VERSION ""

NS_ :

BS_:

BU_: Vector__XXX

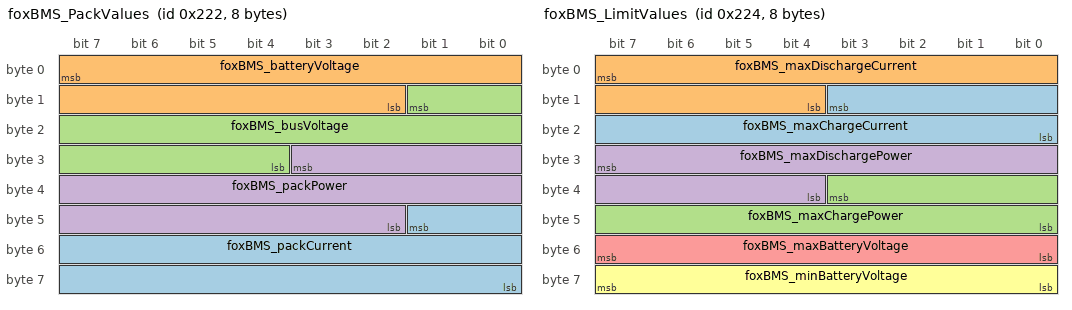
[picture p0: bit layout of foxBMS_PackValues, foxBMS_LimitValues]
BO_ 546 foxBMS_PackValues: 8 Vector__XXX
SG_ foxBMS_packCurrent : 41|18@0- (0.01,0) [-1310.72|1310.71] "A" Vector__XXX
SG_ foxBMS_batteryVoltage : 7|14@0+ (0.1,0) [0|1638.3] "V" Vector__XXX
SG_ foxBMS_busVoltage : 9|14@0+ (0.1,0) [0|1638.3] "V" Vector__XXX
SG_ foxBMS_packPower : 27|18@0- (0.01,0) [-1310.72|1310.71] "kW" Vector__XXX

BO_ 548 foxBMS_LimitValues: 8 Vector__XXX
SG_ foxBMS_maxChargeCurrent : 11|12@0+ (0.25,0) [0|1023.75] "A" Vector__XXX
SG_ foxBMS_maxDischargeCurrent : 7|12@0+ (0.25,0) [0|1023.75] "A" Vector__XXX
SG_ foxBMS_maxChargePower : 35|12@0+ (0.2,0) [0|819] "kW" Vector__XXX
SG_ foxBMS_maxDischargePower : 31|12@0+ (0.1,0) [0|409.5] "kW" Vector__XXX
SG_ foxBMS_maxBatteryVoltage : 55|8@0+ (4,0) [0|1020] "V" Vector__XXX
SG_ foxBMS_minBatteryVoltage : 63|8@0+ (4,0) [0|1020] "V" Vector__XXX

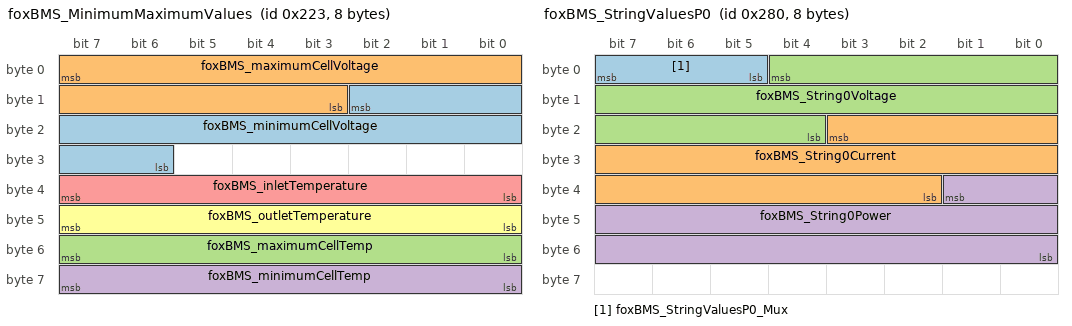
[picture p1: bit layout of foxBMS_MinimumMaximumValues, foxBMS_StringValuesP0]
BO_ 547 foxBMS_MinimumMaximumValues: 8 Vector__XXX
SG_ foxBMS_minimumCellVoltage : 10|13@0+ (1,0) [0|8191] "mV" Vector__XXX
SG_ foxBMS_maximumCellVoltage : 7|13@0+ (1,0) [0|8191] "mV" Vector__XXX
SG_ foxBMS_maximumCellTemp : 55|8@0- (1,0) [-128|127] "degC" Vector__XXX
SG_ foxBMS_minimumCellTemp : 63|8@0- (1,0) [-128|127] "degC" Vector__XXX
SG_ foxBMS_inletTemperature : 39|8@0- (1,0) [-128|127] "degC" Vector__XXX
SG_ foxBMS_outletTemperature : 47|8@0- (1,0) [-128|127] "degC" Vector__XXX

BO_ 640 foxBMS_StringValuesP0: 8 Vector__XXX
SG_ foxBMS_StringValuesP0_Mux M : 7|3@0+ (1,0) [0|0] "" Vector__XXX
SG_ foxBMS_String0Current : 19|18@0- (0.01,0) [-1310.72|1310.71] "A" Vector__XXX
SG_ foxBMS_String0Voltage : 4|17@0+ (0.01,0) [0|1310.71] "V" Vector__XXX
SG_ foxBMS_String0Power : 33|18@0- (0.01,0) [-1310.72|1310.71] "kW" Vector__XXX

BO_ 643 foxBMS_StringValuesP1: 8 Vector__XXX
SG_ foxBMS_StringValuesP1_Mux M : 7|4@0+ (1,0) [0|0] "" Vector__XXX
SG_ foxBMS_String0EnergyCount : 15|32@0- (1,0) [-2147483648|2147483647] "Wh" Vector__XXX

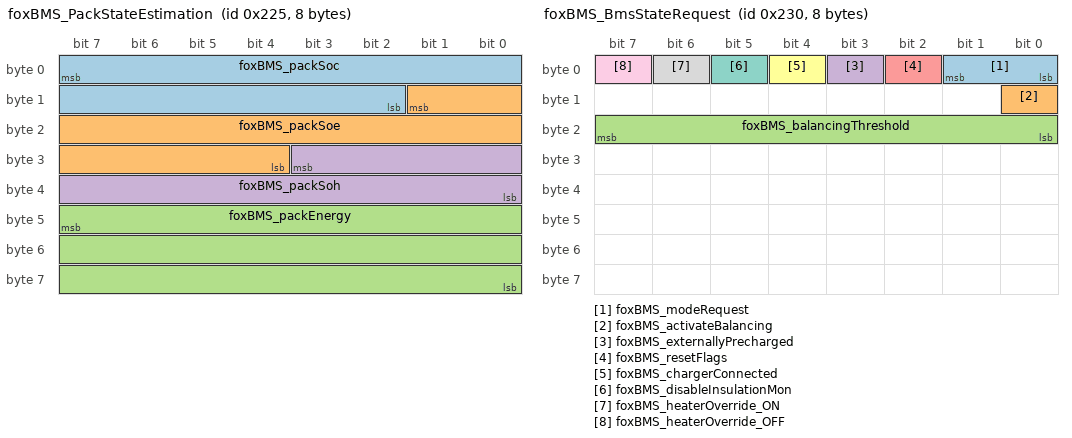
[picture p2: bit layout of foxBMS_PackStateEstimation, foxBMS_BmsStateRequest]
BO_ 549 foxBMS_PackStateEstimation: 8 Vector__XXX
SG_ foxBMS_packSoc : 7|14@0+ (0.01,0) [0|163.83] "%" Vector__XXX
SG_ foxBMS_packSoe : 9|14@0+ (0.01,0) [0|163.83] "%" Vector__XXX
SG_ foxBMS_packEnergy : 47|24@0+ (0.01,0) [0|167772.15] "kWh" Vector__XXX
SG_ foxBMS_packSoh : 27|12@0+ (0.025,0) [0|102.375] "%" Vector__XXX

BO_ 576 foxBMS_CellVoltages: 8 Vector__XXX
SG_ foxBMS_CellVoltages_Mux M : 7|8@0+ (1,0) [0|0] "" Vector__XXX
SG_ cellVoltage_000_invalidFlag m0 : 12|1@0+ (1,0) [0|1] "" Vector__XXX
SG_ cellVoltage_001_invalidFlag m0 : 13|1@0+ (1,0) [0|1] "" Vector__XXX
SG_ cellVoltage_002_invalidFlag m0 : 14|1@0+ (1,0) [0|1] "" Vector__XXX
SG_ cellVoltage_003_invalidFlag m0 : 15|1@0+ (1,0) [0|1] "" Vector__XXX
SG_ cellVoltage_000 m0 : 11|13@0+ (1,0) [0|8191] "mV" Vector__XXX
SG_ cellVoltage_001 m0 : 30|13@0+ (1,0) [0|8191] "mV" Vector__XXX
SG_ cellVoltage_002 m0 : 33|13@0+ (1,0) [0|8191] "mV" Vector__XXX
SG_ cellVoltage_003 m0 : 52|13@0+ (1,0) [0|8191] "mV" Vector__XXX
SG_ cellVoltage_004_invalidFlag m1 : 12|1@0+ (1,0) [0|1] "" Vector__XXX
SG_ cellVoltage_005_invalidFlag m1 : 13|1@0+ (1,0) [0|1] "" Vector__XXX
SG_ cellVoltage_006_invalidFlag m1 : 14|1@0+ (1,0) [0|1] "" Vector__XXX
SG_ cellVoltage_007_invalidFlag m1 : 15|1@0+ (1,0) [0|1] "" Vector__XXX
SG_ cellVoltage_004 m1 : 11|13@0+ (1,0) [0|8191] "mV" Vector__XXX
SG_ cellVoltage_005 m1 : 30|13@0+ (1,0) [0|8191] "mV" Vector__XXX
SG_ cellVoltage_006 m1 : 33|13@0+ (1,0) [0|8191] "mV" Vector__XXX
SG_ cellVoltage_007 m1 : 52|13@0+ (1,0) [0|8191] "mV" Vector__XXX
SG_ cellVoltage_008_invalidFlag m2 : 12|1@0+ (1,0) [0|1] "" Vector__XXX
SG_ cellVoltage_009_invalidFlag m2 : 13|1@0+ (1,0) [0|1] "" Vector__XXX
SG_ cellVoltage_010_invalidFlag m2 : 14|1@0+ (1,0) [0|1] "" Vector__XXX
SG_ cellVoltage_011_invalidFlag m2 : 15|1@0+ (1,0) [0|1] "" Vector__XXX
SG_ cellVoltage_008 m2 : 11|13@0+ (1,0) [0|8191] "mV" Vector__XXX
SG_ cellVoltage_009 m2 : 30|13@0+ (1,0) [0|8191] "mV" Vector__XXX
SG_ cellVoltage_010 m2 : 33|13@0+ (1,0) [0|8191] "mV" Vector__XXX
SG_ cellVoltage_011 m2 : 52|13@0+ (1,0) [0|8191] "mV" Vector__XXX
SG_ cellVoltage_012_invalidFlag m3 : 12|1@0+ (1,0) [0|1] "" Vector__XXX
SG_ cellVoltage_013_invalidFlag m3 : 13|1@0+ (1,0) [0|1] "" Vector__XXX
SG_ cellVoltage_014_invalidFlag m3 : 14|1@0+ (1,0) [0|1] "" Vector__XXX
SG_ cellVoltage_015_invalidFlag m3 : 15|1@0+ (1,0) [0|1] "" Vector__XXX
SG_ cellVoltage_012 m3 : 11|13@0+ (1,0) [0|8191] "mV" Vector__XXX
SG_ cellVoltage_013 m3 : 30|13@0+ (1,0) [0|8191] "mV" Vector__XXX
SG_ cellVoltage_014 m3 : 33|13@0+ (1,0) [0|8191] "mV" Vector__XXX
SG_ cellVoltage_015 m3 : 52|13@0+ (1,0) [0|8191] "mV" Vector__XXX
SG_ cellVoltage_016_invalidFlag m4 : 12|1@0+ (1,0) [0|1] "" Vector__XXX
SG_ cellVoltage_017_invalidFlag m4 : 13|1@0+ (1,0) [0|1] "" Vector__XXX
SG_ cellVoltage_018_invalidFlag m4 : 14|1@0+ (1,0) [0|1] "" Vector__XXX
SG_ cellVoltage_019_invalidFlag m4 : 15|1@0+ (1,0) [0|1] "" Vector__XXX
SG_ cellVoltage_016 m4 : 11|13@0+ (1,0) [0|8191] "mV" Vector__XXX
SG_ cellVoltage_017 m4 : 30|13@0+ (1,0) [0|8191] "mV" Vector__XXX
SG_ cellVoltage_018 m4 : 33|13@0+ (1,0) [0|8191] "mV" Vector__XXX
SG_ cellVoltage_019 m4 : 52|13@0+ (1,0) [0|8191] "mV" Vector__XXX
SG_ cellVoltage_020_invalidFlag m5 : 12|1@0+ (1,0) [0|1] "" Vector__XXX
SG_ cellVoltage_021_invalidFlag m5 : 13|1@0+ (1,0) [0|1] "" Vector__XXX
SG_ cellVoltage_022_invalidFlag m5 : 14|1@0+ (1,0) [0|1] "" Vector__XXX
SG_ cellVoltage_023_invalidFlag m5 : 15|1@0+ (1,0) [0|1] "" Vector__XXX
SG_ cellVoltage_020 m5 : 11|13@0+ (1,0) [0|8191] "mV" Vector__XXX
SG_ cellVoltage_021 m5 : 30|13@0+ (1,0) [0|8191] "mV" Vector__XXX
SG_ cellVoltage_022 m5 : 33|13@0+ (1,0) [0|8191] "mV" Vector__XXX
SG_ cellVoltage_023 m5 : 52|13@0+ (1,0) [0|8191] "mV" Vector__XXX
SG_ cellVoltage_024_invalidFlag m6 : 12|1@0+ (1,0) [0|1] "" Vector__XXX
SG_ cellVoltage_025_invalidFlag m6 : 13|1@0+ (1,0) [0|1] "" Vector__XXX
SG_ cellVoltage_026_invalidFlag m6 : 14|1@0+ (1,0) [0|1] "" Vector__XXX
SG_ cellVoltage_027_invalidFlag m6 : 15|1@0+ (1,0) [0|1] "" Vector__XXX
SG_ cellVoltage_024 m6 : 11|13@0+ (1,0) [0|8191] "mV" Vector__XXX
SG_ cellVoltage_025 m6 : 30|13@0+ (1,0) [0|8191] "mV" Vector__XXX
SG_ cellVoltage_026 m6 : 33|13@0+ (1,0) [0|8191] "mV" Vector__XXX
SG_ cellVoltage_027 m6 : 52|13@0+ (1,0) [0|8191] "mV" Vector__XXX
SG_ cellVoltage_028_invalidFlag m7 : 12|1@0+ (1,0) [0|1] "" Vector__XXX
SG_ cellVoltage_029_invalidFlag m7 : 13|1@0+ (1,0) [0|1] "" Vector__XXX
SG_ cellVoltage_030_invalidFlag m7 : 14|1@0+ (1,0) [0|1] "" Vector__XXX
SG_ cellVoltage_031_invalidFlag m7 : 15|1@0+ (1,0) [0|1] "" Vector__XXX
SG_ cellVoltage_028 m7 : 11|13@0+ (1,0) [0|8191] "mV" Vector__XXX
SG_ cellVoltage_029 m7 : 30|13@0+ (1,0) [0|8191] "mV" Vector__XXX
SG_ cellVoltage_030 m7 : 33|13@0+ (1,0) [0|8191] "mV" Vector__XXX
SG_ cellVoltage_031 m7 : 52|13@0+ (1,0) [0|8191] "mV" Vector__XXX
SG_ cellVoltage_032_invalidFlag m8 : 12|1@0+ (1,0) [0|1] "" Vector__XXX
SG_ cellVoltage_033_invalidFlag m8 : 13|1@0+ (1,0) [0|1] "" Vector__XXX
SG_ cellVoltage_034_invalidFlag m8 : 14|1@0+ (1,0) [0|1] "" Vector__XXX
SG_ cellVoltage_035_invalidFlag m8 : 15|1@0+ (1,0) [0|1] "" Vector__XXX
SG_ cellVoltage_032 m8 : 11|13@0+ (1,0) [0|8191] "mV" Vector__XXX
SG_ cellVoltage_033 m8 : 30|13@0+ (1,0) [0|8191] "mV" Vector__XXX
SG_ cellVoltage_034 m8 : 33|13@0+ (1,0) [0|8191] "mV" Vector__XXX
SG_ cellVoltage_035 m8 : 52|13@0+ (1,0) [0|8191] "mV" Vector__XXX
SG_ cellVoltage_036_invalidFlag m9 : 12|1@0+ (1,0) [0|1] "" Vector__XXX
SG_ cellVoltage_037_invalidFlag m9 : 13|1@0+ (1,0) [0|1] "" Vector__XXX
SG_ cellVoltage_038_invalidFlag m9 : 14|1@0+ (1,0) [0|1] "" Vector__XXX
SG_ cellVoltage_039_invalidFlag m9 : 15|1@0+ (1,0) [0|1] "" Vector__XXX
SG_ cellVoltage_036 m9 : 11|13@0+ (1,0) [0|8191] "mV" Vector__XXX
SG_ cellVoltage_037 m9 : 30|13@0+ (1,0) [0|8191] "mV" Vector__XXX
SG_ cellVoltage_038 m9 : 33|13@0+ (1,0) [0|8191] "mV" Vector__XXX
SG_ cellVoltage_039 m9 : 52|13@0+ (1,0) [0|8191] "mV" Vector__XXX
SG_ cellVoltage_040_invalidFlag m10 : 12|1@0+ (1,0) [0|1] "" Vector__XXX
SG_ cellVoltage_041_invalidFlag m10 : 13|1@0+ (1,0) [0|1] "" Vector__XXX
SG_ cellVoltage_042_invalidFlag m10 : 14|1@0+ (1,0) [0|1] "" Vector__XXX
SG_ cellVoltage_043_invalidFlag m10 : 15|1@0+ (1,0) [0|1] "" Vector__XXX
SG_ cellVoltage_040 m10 : 11|13@0+ (1,0) [0|8191] "mV" Vector__XXX
SG_ cellVoltage_041 m10 : 30|13@0+ (1,0) [0|8191] "mV" Vector__XXX
SG_ cellVoltage_042 m10 : 33|13@0+ (1,0) [0|8191] "mV" Vector__XXX
SG_ cellVoltage_043 m10 : 52|13@0+ (1,0) [0|8191] "mV" Vector__XXX
SG_ cellVoltage_044_invalidFlag m11 : 12|1@0+ (1,0) [0|1] "" Vector__XXX
SG_ cellVoltage_045_invalidFlag m11 : 13|1@0+ (1,0) [0|1] "" Vector__XXX
SG_ cellVoltage_046_invalidFlag m11 : 14|1@0+ (1,0) [0|1] "" Vector__XXX
SG_ cellVoltage_047_invalidFlag m11 : 15|1@0+ (1,0) [0|1] "" Vector__XXX
SG_ cellVoltage_044 m11 : 11|13@0+ (1,0) [0|8191] "mV" Vector__XXX
SG_ cellVoltage_045 m11 : 30|13@0+ (1,0) [0|8191] "mV" Vector__XXX
SG_ cellVoltage_046 m11 : 33|13@0+ (1,0) [0|8191] "mV" Vector__XXX
SG_ cellVoltage_047 m11 : 52|13@0+ (1,0) [0|8191] "mV" Vector__XXX
SG_ cellVoltage_048_invalidFlag m12 : 12|1@0+ (1,0) [0|1] "" Vector__XXX
SG_ cellVoltage_049_invalidFlag m12 : 13|1@0+ (1,0) [0|1] "" Vector__XXX
SG_ cellVoltage_050_invalidFlag m12 : 14|1@0+ (1,0) [0|1] "" Vector__XXX
SG_ cellVoltage_051_invalidFlag m12 : 15|1@0+ (1,0) [0|1] "" Vector__XXX
SG_ cellVoltage_048 m12 : 11|13@0+ (1,0) [0|8191] "mV" Vector__XXX
SG_ cellVoltage_049 m12 : 30|13@0+ (1,0) [0|8191] "mV" Vector__XXX
SG_ cellVoltage_050 m12 : 33|13@0+ (1,0) [0|8191] "mV" Vector__XXX
SG_ cellVoltage_051 m12 : 52|13@0+ (1,0) [0|8191] "mV" Vector__XXX
SG_ cellVoltage_052_invalidFlag m13 : 12|1@0+ (1,0) [0|1] "" Vector__XXX
SG_ cellVoltage_053_invalidFlag m13 : 13|1@0+ (1,0) [0|1] "" Vector__XXX
SG_ cellVoltage_054_invalidFlag m13 : 14|1@0+ (1,0) [0|1] "" Vector__XXX
SG_ cellVoltage_055_invalidFlag m13 : 15|1@0+ (1,0) [0|1] "" Vector__XXX
SG_ cellVoltage_052 m13 : 11|13@0+ (1,0) [0|8191] "mV" Vector__XXX
SG_ cellVoltage_053 m13 : 30|13@0+ (1,0) [0|8191] "mV" Vector__XXX
SG_ cellVoltage_054 m13 : 33|13@0+ (1,0) [0|8191] "mV" Vector__XXX
SG_ cellVoltage_055 m13 : 52|13@0+ (1,0) [0|8191] "mV" Vector__XXX
SG_ cellVoltage_056_invalidFlag m14 : 12|1@0+ (1,0) [0|1] "" Vector__XXX
SG_ cellVoltage_057_invalidFlag m14 : 13|1@0+ (1,0) [0|1] "" Vector__XXX
SG_ cellVoltage_058_invalidFlag m14 : 14|1@0+ (1,0) [0|1] "" Vector__XXX
SG_ cellVoltage_059_invalidFlag m14 : 15|1@0+ (1,0) [0|1] "" Vector__XXX
SG_ cellVoltage_056 m14 : 11|13@0+ (1,0) [0|8191] "mV" Vector__XXX
SG_ cellVoltage_057 m14 : 30|13@0+ (1,0) [0|8191] "mV" Vector__XXX
SG_ cellVoltage_058 m14 : 33|13@0+ (1,0) [0|8191] "mV" Vector__XXX
SG_ cellVoltage_059 m14 : 52|13@0+ (1,0) [0|8191] "mV" Vector__XXX
SG_ cellVoltage_060_invalidFlag m15 : 12|1@0+ (1,0) [0|1] "" Vector__XXX
SG_ cellVoltage_061_invalidFlag m15 : 13|1@0+ (1,0) [0|1] "" Vector__XXX
SG_ cellVoltage_062_invalidFlag m15 : 14|1@0+ (1,0) [0|1] "" Vector__XXX
SG_ cellVoltage_063_invalidFlag m15 : 15|1@0+ (1,0) [0|1] "" Vector__XXX
SG_ cellVoltage_060 m15 : 11|13@0+ (1,0) [0|8191] "mV" Vector__XXX
SG_ cellVoltage_061 m15 : 30|13@0+ (1,0) [0|8191] "mV" Vector__XXX
SG_ cellVoltage_062 m15 : 33|13@0+ (1,0) [0|8191] "mV" Vector__XXX
SG_ cellVoltage_063 m15 : 52|13@0+ (1,0) [0|8191] "mV" Vector__XXX
SG_ cellVoltage_064_invalidFlag m16 : 12|1@0+ (1,0) [0|1] "" Vector__XXX
SG_ cellVoltage_065_invalidFlag m16 : 13|1@0+ (1,0) [0|1] "" Vector__XXX
SG_ cellVoltage_066_invalidFlag m16 : 14|1@0+ (1,0) [0|1] "" Vector__XXX
SG_ cellVoltage_067_invalidFlag m16 : 15|1@0+ (1,0) [0|1] "" Vector__XXX
SG_ cellVoltage_064 m16 : 11|13@0+ (1,0) [0|8191] "mV" Vector__XXX
SG_ cellVoltage_065 m16 : 30|13@0+ (1,0) [0|8191] "mV" Vector__XXX
SG_ cellVoltage_066 m16 : 33|13@0+ (1,0) [0|8191] "mV" Vector__XXX
SG_ cellVoltage_067 m16 : 52|13@0+ (1,0) [0|8191] "mV" Vector__XXX
SG_ cellVoltage_068_invalidFlag m17 : 12|1@0+ (1,0) [0|1] "" Vector__XXX
SG_ cellVoltage_069_invalidFlag m17 : 13|1@0+ (1,0) [0|1] "" Vector__XXX
SG_ cellVoltage_070_invalidFlag m17 : 14|1@0+ (1,0) [0|1] "" Vector__XXX
SG_ cellVoltage_071_invalidFlag m17 : 15|1@0+ (1,0) [0|1] "" Vector__XXX
SG_ cellVoltage_068 m17 : 11|13@0+ (1,0) [0|8191] "mV" Vector__XXX
SG_ cellVoltage_069 m17 : 30|13@0+ (1,0) [0|8191] "mV" Vector__XXX
SG_ cellVoltage_070 m17 : 33|13@0+ (1,0) [0|8191] "mV" Vector__XXX
SG_ cellVoltage_071 m17 : 52|13@0+ (1,0) [0|8191] "mV" Vector__XXX
SG_ cellVoltage_072_invalidFlag m18 : 12|1@0+ (1,0) [0|1] "" Vector__XXX
SG_ cellVoltage_073_invalidFlag m18 : 13|1@0+ (1,0) [0|1] "" Vector__XXX
SG_ cellVoltage_074_invalidFlag m18 : 14|1@0+ (1,0) [0|1] "" Vector__XXX
SG_ cellVoltage_075_invalidFlag m18 : 15|1@0+ (1,0) [0|1] "" Vector__XXX
SG_ cellVoltage_072 m18 : 11|13@0+ (1,0) [0|8191] "mV" Vector__XXX
SG_ cellVoltage_073 m18 : 30|13@0+ (1,0) [0|8191] "mV" Vector__XXX
SG_ cellVoltage_074 m18 : 33|13@0+ (1,0) [0|8191] "mV" Vector__XXX
SG_ cellVoltage_075 m18 : 52|13@0+ (1,0) [0|8191] "mV" Vector__XXX
SG_ cellVoltage_076_invalidFlag m19 : 12|1@0+ (1,0) [0|1] "" Vector__XXX
SG_ cellVoltage_077_invalidFlag m19 : 13|1@0+ (1,0) [0|1] "" Vector__XXX
SG_ cellVoltage_078_invalidFlag m19 : 14|1@0+ (1,0) [0|1] "" Vector__XXX
SG_ cellVoltage_079_invalidFlag m19 : 15|1@0+ (1,0) [0|1] "" Vector__XXX
SG_ cellVoltage_076 m19 : 11|13@0+ (1,0) [0|8191] "mV" Vector__XXX
SG_ cellVoltage_077 m19 : 30|13@0+ (1,0) [0|8191] "mV" Vector__XXX
SG_ cellVoltage_078 m19 : 33|13@0+ (1,0) [0|8191] "mV" Vector__XXX
SG_ cellVoltage_079 m19 : 52|13@0+ (1,0) [0|8191] "mV" Vector__XXX
SG_ cellVoltage_080_invalidFlag m20 : 12|1@0+ (1,0) [0|1] "" Vector__XXX
SG_ cellVoltage_081_invalidFlag m20 : 13|1@0+ (1,0) [0|1] "" Vector__XXX
SG_ cellVoltage_082_invalidFlag m20 : 14|1@0+ (1,0) [0|1] "" Vector__XXX
SG_ cellVoltage_083_invalidFlag m20 : 15|1@0+ (1,0) [0|1] "" Vector__XXX
SG_ cellVoltage_080 m20 : 11|13@0+ (1,0) [0|8191] "mV" Vector__XXX
SG_ cellVoltage_081 m20 : 30|13@0+ (1,0) [0|8191] "mV" Vector__XXX
SG_ cellVoltage_082 m20 : 33|13@0+ (1,0) [0|8191] "mV" Vector__XXX
SG_ cellVoltage_083 m20 : 52|13@0+ (1,0) [0|8191] "mV" Vector__XXX
SG_ cellVoltage_084_invalidFlag m21 : 12|1@0+ (1,0) [0|1] "" Vector__XXX
SG_ cellVoltage_085_invalidFlag m21 : 13|1@0+ (1,0) [0|1] "" Vector__XXX
SG_ cellVoltage_086_invalidFlag m21 : 14|1@0+ (1,0) [0|1] "" Vector__XXX
SG_ cellVoltage_087_invalidFlag m21 : 15|1@0+ (1,0) [0|1] "" Vector__XXX
SG_ cellVoltage_084 m21 : 11|13@0+ (1,0) [0|8191] "mV" Vector__XXX
SG_ cellVoltage_085 m21 : 30|13@0+ (1,0) [0|8191] "mV" Vector__XXX
SG_ cellVoltage_086 m21 : 33|13@0+ (1,0) [0|8191] "mV" Vector__XXX
SG_ cellVoltage_087 m21 : 52|13@0+ (1,0) [0|8191] "mV" Vector__XXX
SG_ cellVoltage_088_invalidFlag m22 : 12|1@0+ (1,0) [0|1] "" Vector__XXX
SG_ cellVoltage_089_invalidFlag m22 : 13|1@0+ (1,0) [0|1] "" Vector__XXX
SG_ cellVoltage_090_invalidFlag m22 : 14|1@0+ (1,0) [0|1] "" Vector__XXX
SG_ cellVoltage_091_invalidFlag m22 : 15|1@0+ (1,0) [0|1] "" Vector__XXX
SG_ cellVoltage_088 m22 : 11|13@0+ (1,0) [0|8191] "mV" Vector__XXX
SG_ cellVoltage_089 m22 : 30|13@0+ (1,0) [0|8191] "mV" Vector__XXX
SG_ cellVoltage_090 m22 : 33|13@0+ (1,0) [0|8191] "mV" Vector__XXX
SG_ cellVoltage_091 m22 : 52|13@0+ (1,0) [0|8191] "mV" Vector__XXX
SG_ cellVoltage_092_invalidFlag m23 : 12|1@0+ (1,0) [0|1] "" Vector__XXX
SG_ cellVoltage_093_invalidFlag m23 : 13|1@0+ (1,0) [0|1] "" Vector__XXX
SG_ cellVoltage_094_invalidFlag m23 : 14|1@0+ (1,0) [0|1] "" Vector__XXX
SG_ cellVoltage_095_invalidFlag m23 : 15|1@0+ (1,0) [0|1] "" Vector__XXX
SG_ cellVoltage_092 m23 : 11|13@0+ (1,0) [0|8191] "mV" Vector__XXX
SG_ cellVoltage_093 m23 : 30|13@0+ (1,0) [0|8191] "mV" Vector__XXX
SG_ cellVoltage_094 m23 : 33|13@0+ (1,0) [0|8191] "mV" Vector__XXX
SG_ cellVoltage_095 m23 : 52|13@0+ (1,0) [0|8191] "mV" Vector__XXX
SG_ cellVoltage_096_invalidFlag m24 : 12|1@0+ (1,0) [0|1] "" Vector__XXX
SG_ cellVoltage_097_invalidFlag m24 : 13|1@0+ (1,0) [0|1] "" Vector__XXX
SG_ cellVoltage_098_invalidFlag m24 : 14|1@0+ (1,0) [0|1] "" Vector__XXX
SG_ cellVoltage_099_invalidFlag m24 : 15|1@0+ (1,0) [0|1] "" Vector__XXX
SG_ cellVoltage_096 m24 : 11|13@0+ (1,0) [0|8191] "mV" Vector__XXX
SG_ cellVoltage_097 m24 : 30|13@0+ (1,0) [0|8191] "mV" Vector__XXX
SG_ cellVoltage_098 m24 : 33|13@0+ (1,0) [0|8191] "mV" Vector__XXX
SG_ cellVoltage_099 m24 : 52|13@0+ (1,0) [0|8191] "mV" Vector__XXX
SG_ cellVoltage_100_invalidFlag m25 : 12|1@0+ (1,0) [0|1] "" Vector__XXX
SG_ cellVoltage_101_invalidFlag m25 : 13|1@0+ (1,0) [0|1] "" Vector__XXX
SG_ cellVoltage_102_invalidFlag m25 : 14|1@0+ (1,0) [0|1] "" Vector__XXX
SG_ cellVoltage_103_invalidFlag m25 : 15|1@0+ (1,0) [0|1] "" Vector__XXX
SG_ cellVoltage_100 m25 : 11|13@0+ (1,0) [0|8191] "mV" Vector__XXX
SG_ cellVoltage_101 m25 : 30|13@0+ (1,0) [0|8191] "mV" Vector__XXX
SG_ cellVoltage_102 m25 : 33|13@0+ (1,0) [0|8191] "mV" Vector__XXX
SG_ cellVoltage_103 m25 : 52|13@0+ (1,0) [0|8191] "mV" Vector__XXX
SG_ cellVoltage_104_invalidFlag m26 : 12|1@0+ (1,0) [0|1] "" Vector__XXX
SG_ cellVoltage_105_invalidFlag m26 : 13|1@0+ (1,0) [0|1] "" Vector__XXX
SG_ cellVoltage_106_invalidFlag m26 : 14|1@0+ (1,0) [0|1] "" Vector__XXX
SG_ cellVoltage_107_invalidFlag m26 : 15|1@0+ (1,0) [0|1] "" Vector__XXX
SG_ cellVoltage_104 m26 : 11|13@0+ (1,0) [0|8191] "mV" Vector__XXX
SG_ cellVoltage_105 m26 : 30|13@0+ (1,0) [0|8191] "mV" Vector__XXX
SG_ cellVoltage_106 m26 : 33|13@0+ (1,0) [0|8191] "mV" Vector__XXX
SG_ cellVoltage_107 m26 : 52|13@0+ (1,0) [0|8191] "mV" Vector__XXX
SG_ cellVoltage_108_invalidFlag m27 : 12|1@0+ (1,0) [0|1] "" Vector__XXX
SG_ cellVoltage_109_invalidFlag m27 : 13|1@0+ (1,0) [0|1] "" Vector__XXX
SG_ cellVoltage_110_invalidFlag m27 : 14|1@0+ (1,0) [0|1] "" Vector__XXX
SG_ cellVoltage_111_invalidFlag m27 : 15|1@0+ (1,0) [0|1] "" Vector__XXX
SG_ cellVoltage_108 m27 : 11|13@0+ (1,0) [0|8191] "mV" Vector__XXX
SG_ cellVoltage_109 m27 : 30|13@0+ (1,0) [0|8191] "mV" Vector__XXX
SG_ cellVoltage_110 m27 : 33|13@0+ (1,0) [0|8191] "mV" Vector__XXX
SG_ cellVoltage_111 m27 : 52|13@0+ (1,0) [0|8191] "mV" Vector__XXX
SG_ cellVoltage_112_invalidFlag m28 : 12|1@0+ (1,0) [0|1] "" Vector__XXX
SG_ cellVoltage_113_invalidFlag m28 : 13|1@0+ (1,0) [0|1] "" Vector__XXX
SG_ cellVoltage_114_invalidFlag m28 : 14|1@0+ (1,0) [0|1] "" Vector__XXX
SG_ cellVoltage_115_invalidFlag m28 : 15|1@0+ (1,0) [0|1] "" Vector__XXX
SG_ cellVoltage_112 m28 : 11|13@0+ (1,0) [0|8191] "mV" Vector__XXX
SG_ cellVoltage_113 m28 : 30|13@0+ (1,0) [0|8191] "mV" Vector__XXX
SG_ cellVoltage_114 m28 : 33|13@0+ (1,0) [0|8191] "mV" Vector__XXX
SG_ cellVoltage_115 m28 : 52|13@0+ (1,0) [0|8191] "mV" Vector__XXX
SG_ cellVoltage_116_invalidFlag m29 : 12|1@0+ (1,0) [0|1] "" Vector__XXX
SG_ cellVoltage_117_invalidFlag m29 : 13|1@0+ (1,0) [0|1] "" Vector__XXX
SG_ cellVoltage_118_invalidFlag m29 : 14|1@0+ (1,0) [0|1] "" Vector__XXX
SG_ cellVoltage_119_invalidFlag m29 : 15|1@0+ (1,0) [0|1] "" Vector__XXX
SG_ cellVoltage_116 m29 : 11|13@0+ (1,0) [0|8191] "mV" Vector__XXX
SG_ cellVoltage_117 m29 : 30|13@0+ (1,0) [0|8191] "mV" Vector__XXX
SG_ cellVoltage_118 m29 : 33|13@0+ (1,0) [0|8191] "mV" Vector__XXX
SG_ cellVoltage_119 m29 : 52|13@0+ (1,0) [0|8191] "mV" Vector__XXX
SG_ cellVoltage_120_invalidFlag m30 : 12|1@0+ (1,0) [0|1] "" Vector__XXX
SG_ cellVoltage_121_invalidFlag m30 : 13|1@0+ (1,0) [0|1] "" Vector__XXX
SG_ cellVoltage_122_invalidFlag m30 : 14|1@0+ (1,0) [0|1] "" Vector__XXX
SG_ cellVoltage_123_invalidFlag m30 : 15|1@0+ (1,0) [0|1] "" Vector__XXX
SG_ cellVoltage_120 m30 : 11|13@0+ (1,0) [0|8191] "mV" Vector__XXX
SG_ cellVoltage_121 m30 : 30|13@0+ (1,0) [0|8191] "mV" Vector__XXX
SG_ cellVoltage_122 m30 : 33|13@0+ (1,0) [0|8191] "mV" Vector__XXX
SG_ cellVoltage_123 m30 : 52|13@0+ (1,0) [0|8191] "mV" Vector__XXX
SG_ cellVoltage_124_invalidFlag m31 : 12|1@0+ (1,0) [0|1] "" Vector__XXX
SG_ cellVoltage_125_invalidFlag m31 : 13|1@0+ (1,0) [0|1] "" Vector__XXX
SG_ cellVoltage_126_invalidFlag m31 : 14|1@0+ (1,0) [0|1] "" Vector__XXX
SG_ cellVoltage_127_invalidFlag m31 : 15|1@0+ (1,0) [0|1] "" Vector__XXX
SG_ cellVoltage_124 m31 : 11|13@0+ (1,0) [0|8191] "mV" Vector__XXX
SG_ cellVoltage_125 m31 : 30|13@0+ (1,0) [0|8191] "mV" Vector__XXX
SG_ cellVoltage_126 m31 : 33|13@0+ (1,0) [0|8191] "mV" Vector__XXX
SG_ cellVoltage_127 m31 : 52|13@0+ (1,0) [0|8191] "mV" Vector__XXX
SG_ cellVoltage_128_invalidFlag m32 : 12|1@0+ (1,0) [0|1] "" Vector__XXX
SG_ cellVoltage_129_invalidFlag m32 : 13|1@0+ (1,0) [0|1] "" Vector__XXX
SG_ cellVoltage_130_invalidFlag m32 : 14|1@0+ (1,0) [0|1] "" Vector__XXX
SG_ cellVoltage_131_invalidFlag m32 : 15|1@0+ (1,0) [0|1] "" Vector__XXX
SG_ cellVoltage_128 m32 : 11|13@0+ (1,0) [0|8191] "mV" Vector__XXX
SG_ cellVoltage_129 m32 : 30|13@0+ (1,0) [0|8191] "mV" Vector__XXX
SG_ cellVoltage_130 m32 : 33|13@0+ (1,0) [0|8191] "mV" Vector__XXX
SG_ cellVoltage_131 m32 : 52|13@0+ (1,0) [0|8191] "mV" Vector__XXX
SG_ cellVoltage_132_invalidFlag m33 : 12|1@0+ (1,0) [0|1] "" Vector__XXX
SG_ cellVoltage_133_invalidFlag m33 : 13|1@0+ (1,0) [0|1] "" Vector__XXX
SG_ cellVoltage_134_invalidFlag m33 : 14|1@0+ (1,0) [0|1] "" Vector__XXX
SG_ cellVoltage_135_invalidFlag m33 : 15|1@0+ (1,0) [0|1] "" Vector__XXX
SG_ cellVoltage_132 m33 : 11|13@0+ (1,0) [0|8191] "mV" Vector__XXX
SG_ cellVoltage_133 m33 : 30|13@0+ (1,0) [0|8191] "mV" Vector__XXX
SG_ cellVoltage_134 m33 : 33|13@0+ (1,0) [0|8191] "mV" Vector__XXX
SG_ cellVoltage_135 m33 : 52|13@0+ (1,0) [0|8191] "mV" Vector__XXX
SG_ cellVoltage_136_invalidFlag m34 : 12|1@0+ (1,0) [0|1] "" Vector__XXX
SG_ cellVoltage_137_invalidFlag m34 : 13|1@0+ (1,0) [0|1] "" Vector__XXX
SG_ cellVoltage_138_invalidFlag m34 : 14|1@0+ (1,0) [0|1] "" Vector__XXX
SG_ cellVoltage_139_invalidFlag m34 : 15|1@0+ (1,0) [0|1] "" Vector__XXX
SG_ cellVoltage_136 m34 : 11|13@0+ (1,0) [0|8191] "mV" Vector__XXX
SG_ cellVoltage_137 m34 : 30|13@0+ (1,0) [0|8191] "mV" Vector__XXX
SG_ cellVoltage_138 m34 : 33|13@0+ (1,0) [0|8191] "mV" Vector__XXX
SG_ cellVoltage_139 m34 : 52|13@0+ (1,0) [0|8191] "mV" Vector__XXX
SG_ cellVoltage_140_invalidFlag m35 : 12|1@0+ (1,0) [0|1] "" Vector__XXX
SG_ cellVoltage_141_invalidFlag m35 : 13|1@0+ (1,0) [0|1] "" Vector__XXX
SG_ cellVoltage_142_invalidFlag m35 : 14|1@0+ (1,0) [0|1] "" Vector__XXX
SG_ cellVoltage_143_invalidFlag m35 : 15|1@0+ (1,0) [0|1] "" Vector__XXX
SG_ cellVoltage_140 m35 : 11|13@0+ (1,0) [0|8191] "mV" Vector__XXX
SG_ cellVoltage_141 m35 : 30|13@0+ (1,0) [0|8191] "mV" Vector__XXX
SG_ cellVoltage_142 m35 : 33|13@0+ (1,0) [0|8191] "mV" Vector__XXX
SG_ cellVoltage_143 m35 : 52|13@0+ (1,0) [0|8191] "mV" Vector__XXX
SG_ cellVoltage_144_invalidFlag m36 : 12|1@0+ (1,0) [0|1] "" Vector__XXX
SG_ cellVoltage_145_invalidFlag m36 : 13|1@0+ (1,0) [0|1] "" Vector__XXX
SG_ cellVoltage_146_invalidFlag m36 : 14|1@0+ (1,0) [0|1] "" Vector__XXX
SG_ cellVoltage_147_invalidFlag m36 : 15|1@0+ (1,0) [0|1] "" Vector__XXX
SG_ cellVoltage_144 m36 : 11|13@0+ (1,0) [0|8191] "mV" Vector__XXX
SG_ cellVoltage_145 m36 : 30|13@0+ (1,0) [0|8191] "mV" Vector__XXX
SG_ cellVoltage_146 m36 : 33|13@0+ (1,0) [0|8191] "mV" Vector__XXX
SG_ cellVoltage_147 m36 : 52|13@0+ (1,0) [0|8191] "mV" Vector__XXX
SG_ cellVoltage_148_invalidFlag m37 : 12|1@0+ (1,0) [0|1] "" Vector__XXX
SG_ cellVoltage_149_invalidFlag m37 : 13|1@0+ (1,0) [0|1] "" Vector__XXX
SG_ cellVoltage_150_invalidFlag m37 : 14|1@0+ (1,0) [0|1] "" Vector__XXX
SG_ cellVoltage_151_invalidFlag m37 : 15|1@0+ (1,0) [0|1] "" Vector__XXX
SG_ cellVoltage_148 m37 : 11|13@0+ (1,0) [0|8191] "mV" Vector__XXX
SG_ cellVoltage_149 m37 : 30|13@0+ (1,0) [0|8191] "mV" Vector__XXX
SG_ cellVoltage_150 m37 : 33|13@0+ (1,0) [0|8191] "mV" Vector__XXX
SG_ cellVoltage_151 m37 : 52|13@0+ (1,0) [0|8191] "mV" Vector__XXX
SG_ cellVoltage_152_invalidFlag m38 : 12|1@0+ (1,0) [0|1] "" Vector__XXX
SG_ cellVoltage_153_invalidFlag m38 : 13|1@0+ (1,0) [0|1] "" Vector__XXX
SG_ cellVoltage_154_invalidFlag m38 : 14|1@0+ (1,0) [0|1] "" Vector__XXX
SG_ cellVoltage_155_invalidFlag m38 : 15|1@0+ (1,0) [0|1] "" Vector__XXX
SG_ cellVoltage_152 m38 : 11|13@0+ (1,0) [0|8191] "mV" Vector__XXX
SG_ cellVoltage_153 m38 : 30|13@0+ (1,0) [0|8191] "mV" Vector__XXX
SG_ cellVoltage_154 m38 : 33|13@0+ (1,0) [0|8191] "mV" Vector__XXX
SG_ cellVoltage_155 m38 : 52|13@0+ (1,0) [0|8191] "mV" Vector__XXX
SG_ cellVoltage_156_invalidFlag m39 : 12|1@0+ (1,0) [0|1] "" Vector__XXX
SG_ cellVoltage_157_invalidFlag m39 : 13|1@0+ (1,0) [0|1] "" Vector__XXX
SG_ cellVoltage_158_invalidFlag m39 : 14|1@0+ (1,0) [0|1] "" Vector__XXX
SG_ cellVoltage_159_invalidFlag m39 : 15|1@0+ (1,0) [0|1] "" Vector__XXX
SG_ cellVoltage_156 m39 : 11|13@0+ (1,0) [0|8191] "mV" Vector__XXX
SG_ cellVoltage_157 m39 : 30|13@0+ (1,0) [0|8191] "mV" Vector__XXX
SG_ cellVoltage_158 m39 : 33|13@0+ (1,0) [0|8191] "mV" Vector__XXX
SG_ cellVoltage_159 m39 : 52|13@0+ (1,0) [0|8191] "mV" Vector__XXX
SG_ cellVoltage_160_invalidFlag m40 : 12|1@0+ (1,0) [0|1] "" Vector__XXX
SG_ cellVoltage_161_invalidFlag m40 : 13|1@0+ (1,0) [0|1] "" Vector__XXX
SG_ cellVoltage_162_invalidFlag m40 : 14|1@0+ (1,0) [0|1] "" Vector__XXX
SG_ cellVoltage_163_invalidFlag m40 : 15|1@0+ (1,0) [0|1] "" Vector__XXX
SG_ cellVoltage_160 m40 : 11|13@0+ (1,0) [0|8191] "mV" Vector__XXX
SG_ cellVoltage_161 m40 : 30|13@0+ (1,0) [0|8191] "mV" Vector__XXX
SG_ cellVoltage_162 m40 : 33|13@0+ (1,0) [0|8191] "mV" Vector__XXX
SG_ cellVoltage_163 m40 : 52|13@0+ (1,0) [0|8191] "mV" Vector__XXX
SG_ cellVoltage_164_invalidFlag m41 : 12|1@0+ (1,0) [0|1] "" Vector__XXX
SG_ cellVoltage_165_invalidFlag m41 : 13|1@0+ (1,0) [0|1] "" Vector__XXX
SG_ cellVoltage_166_invalidFlag m41 : 14|1@0+ (1,0) [0|1] "" Vector__XXX
SG_ cellVoltage_167_invalidFlag m41 : 15|1@0+ (1,0) [0|1] "" Vector__XXX
SG_ cellVoltage_164 m41 : 11|13@0+ (1,0) [0|8191] "mV" Vector__XXX
SG_ cellVoltage_165 m41 : 30|13@0+ (1,0) [0|8191] "mV" Vector__XXX
SG_ cellVoltage_166 m41 : 33|13@0+ (1,0) [0|8191] "mV" Vector__XXX
SG_ cellVoltage_167 m41 : 52|13@0+ (1,0) [0|8191] "mV" Vector__XXX
SG_ cellVoltage_168_invalidFlag m42 : 12|1@0+ (1,0) [0|1] "" Vector__XXX
SG_ cellVoltage_169_invalidFlag m42 : 13|1@0+ (1,0) [0|1] "" Vector__XXX
SG_ cellVoltage_170_invalidFlag m42 : 14|1@0+ (1,0) [0|1] "" Vector__XXX
SG_ cellVoltage_171_invalidFlag m42 : 15|1@0+ (1,0) [0|1] "" Vector__XXX
SG_ cellVoltage_168 m42 : 11|13@0+ (1,0) [0|8191] "mV" Vector__XXX
SG_ cellVoltage_169 m42 : 30|13@0+ (1,0) [0|8191] "mV" Vector__XXX
SG_ cellVoltage_170 m42 : 33|13@0+ (1,0) [0|8191] "mV" Vector__XXX
SG_ cellVoltage_171 m42 : 52|13@0+ (1,0) [0|8191] "mV" Vector__XXX
SG_ cellVoltage_172_invalidFlag m43 : 12|1@0+ (1,0) [0|1] "" Vector__XXX
SG_ cellVoltage_173_invalidFlag m43 : 13|1@0+ (1,0) [0|1] "" Vector__XXX
SG_ cellVoltage_174_invalidFlag m43 : 14|1@0+ (1,0) [0|1] "" Vector__XXX
SG_ cellVoltage_175_invalidFlag m43 : 15|1@0+ (1,0) [0|1] "" Vector__XXX
SG_ cellVoltage_172 m43 : 11|13@0+ (1,0) [0|8191] "mV" Vector__XXX
SG_ cellVoltage_173 m43 : 30|13@0+ (1,0) [0|8191] "mV" Vector__XXX
SG_ cellVoltage_174 m43 : 33|13@0+ (1,0) [0|8191] "mV" Vector__XXX
SG_ cellVoltage_175 m43 : 52|13@0+ (1,0) [0|8191] "mV" Vector__XXX
SG_ cellVoltage_176_invalidFlag m44 : 12|1@0+ (1,0) [0|1] "" Vector__XXX
SG_ cellVoltage_177_invalidFlag m44 : 13|1@0+ (1,0) [0|1] "" Vector__XXX
SG_ cellVoltage_178_invalidFlag m44 : 14|1@0+ (1,0) [0|1] "" Vector__XXX
SG_ cellVoltage_179_invalidFlag m44 : 15|1@0+ (1,0) [0|1] "" Vector__XXX
SG_ cellVoltage_176 m44 : 11|13@0+ (1,0) [0|8191] "mV" Vector__XXX
SG_ cellVoltage_177 m44 : 30|13@0+ (1,0) [0|8191] "mV" Vector__XXX
SG_ cellVoltage_178 m44 : 33|13@0+ (1,0) [0|8191] "mV" Vector__XXX
SG_ cellVoltage_179 m44 : 52|13@0+ (1,0) [0|8191] "mV" Vector__XXX
SG_ cellVoltage_180_invalidFlag m45 : 12|1@0+ (1,0) [0|1] "" Vector__XXX
SG_ cellVoltage_181_invalidFlag m45 : 13|1@0+ (1,0) [0|1] "" Vector__XXX
SG_ cellVoltage_182_invalidFlag m45 : 14|1@0+ (1,0) [0|1] "" Vector__XXX
SG_ cellVoltage_183_invalidFlag m45 : 15|1@0+ (1,0) [0|1] "" Vector__XXX
SG_ cellVoltage_180 m45 : 11|13@0+ (1,0) [0|8191] "mV" Vector__XXX
SG_ cellVoltage_181 m45 : 30|13@0+ (1,0) [0|8191] "mV" Vector__XXX
SG_ cellVoltage_182 m45 : 33|13@0+ (1,0) [0|8191] "mV" Vector__XXX
SG_ cellVoltage_183 m45 : 52|13@0+ (1,0) [0|8191] "mV" Vector__XXX
SG_ cellVoltage_184_invalidFlag m46 : 12|1@0+ (1,0) [0|1] "" Vector__XXX
SG_ cellVoltage_185_invalidFlag m46 : 13|1@0+ (1,0) [0|1] "" Vector__XXX
SG_ cellVoltage_186_invalidFlag m46 : 14|1@0+ (1,0) [0|1] "" Vector__XXX
SG_ cellVoltage_187_invalidFlag m46 : 15|1@0+ (1,0) [0|1] "" Vector__XXX
SG_ cellVoltage_184 m46 : 11|13@0+ (1,0) [0|8191] "mV" Vector__XXX
SG_ cellVoltage_185 m46 : 30|13@0+ (1,0) [0|8191] "mV" Vector__XXX
SG_ cellVoltage_186 m46 : 33|13@0+ (1,0) [0|8191] "mV" Vector__XXX
SG_ cellVoltage_187 m46 : 52|13@0+ (1,0) [0|8191] "mV" Vector__XXX
SG_ cellVoltage_188_invalidFlag m47 : 12|1@0+ (1,0) [0|1] "" Vector__XXX
SG_ cellVoltage_189_invalidFlag m47 : 13|1@0+ (1,0) [0|1] "" Vector__XXX
SG_ cellVoltage_190_invalidFlag m47 : 14|1@0+ (1,0) [0|1] "" Vector__XXX
SG_ cellVoltage_191_invalidFlag m47 : 15|1@0+ (1,0) [0|1] "" Vector__XXX
SG_ cellVoltage_188 m47 : 11|13@0+ (1,0) [0|8191] "mV" Vector__XXX
SG_ cellVoltage_189 m47 : 30|13@0+ (1,0) [0|8191] "mV" Vector__XXX
SG_ cellVoltage_190 m47 : 33|13@0+ (1,0) [0|8191] "mV" Vector__XXX
SG_ cellVoltage_191 m47 : 52|13@0+ (1,0) [0|8191] "mV" Vector__XXX
SG_ cellVoltage_192_invalidFlag m48 : 12|1@0+ (1,0) [0|1] "" Vector__XXX
SG_ cellVoltage_193_invalidFlag m48 : 13|1@0+ (1,0) [0|1] "" Vector__XXX
SG_ cellVoltage_194_invalidFlag m48 : 14|1@0+ (1,0) [0|1] "" Vector__XXX
SG_ cellVoltage_195_invalidFlag m48 : 15|1@0+ (1,0) [0|1] "" Vector__XXX
SG_ cellVoltage_192 m48 : 11|13@0+ (1,0) [0|8191] "mV" Vector__XXX
SG_ cellVoltage_193 m48 : 30|13@0+ (1,0) [0|8191] "mV" Vector__XXX
SG_ cellVoltage_194 m48 : 33|13@0+ (1,0) [0|8191] "mV" Vector__XXX
SG_ cellVoltage_195 m48 : 52|13@0+ (1,0) [0|8191] "mV" Vector__XXX
SG_ cellVoltage_196_invalidFlag m49 : 12|1@0+ (1,0) [0|1] "" Vector__XXX
SG_ cellVoltage_197_invalidFlag m49 : 13|1@0+ (1,0) [0|1] "" Vector__XXX
SG_ cellVoltage_198_invalidFlag m49 : 14|1@0+ (1,0) [0|1] "" Vector__XXX
SG_ cellVoltage_199_invalidFlag m49 : 15|1@0+ (1,0) [0|1] "" Vector__XXX
SG_ cellVoltage_196 m49 : 11|13@0+ (1,0) [0|8191] "mV" Vector__XXX
SG_ cellVoltage_197 m49 : 30|13@0+ (1,0) [0|8191] "mV" Vector__XXX
SG_ cellVoltage_198 m49 : 33|13@0+ (1,0) [0|8191] "mV" Vector__XXX
SG_ cellVoltage_199 m49 : 52|13@0+ (1,0) [0|8191] "mV" Vector__XXX
SG_ cellVoltage_200_invalidFlag m50 : 12|1@0+ (1,0) [0|1] "" Vector__XXX
SG_ cellVoltage_201_invalidFlag m50 : 13|1@0+ (1,0) [0|1] "" Vector__XXX
SG_ cellVoltage_202_invalidFlag m50 : 14|1@0+ (1,0) [0|1] "" Vector__XXX
SG_ cellVoltage_203_invalidFlag m50 : 15|1@0+ (1,0) [0|1] "" Vector__XXX
SG_ cellVoltage_200 m50 : 11|13@0+ (1,0) [0|8191] "mV" Vector__XXX
SG_ cellVoltage_201 m50 : 30|13@0+ (1,0) [0|8191] "mV" Vector__XXX
SG_ cellVoltage_202 m50 : 33|13@0+ (1,0) [0|8191] "mV" Vector__XXX
SG_ cellVoltage_203 m50 : 52|13@0+ (1,0) [0|8191] "mV" Vector__XXX
SG_ cellVoltage_204_invalidFlag m51 : 12|1@0+ (1,0) [0|1] "" Vector__XXX
SG_ cellVoltage_205_invalidFlag m51 : 13|1@0+ (1,0) [0|1] "" Vector__XXX
SG_ cellVoltage_206_invalidFlag m51 : 14|1@0+ (1,0) [0|1] "" Vector__XXX
SG_ cellVoltage_207_invalidFlag m51 : 15|1@0+ (1,0) [0|1] "" Vector__XXX
SG_ cellVoltage_204 m51 : 11|13@0+ (1,0) [0|8191] "mV" Vector__XXX
SG_ cellVoltage_205 m51 : 30|13@0+ (1,0) [0|8191] "mV" Vector__XXX
SG_ cellVoltage_206 m51 : 33|13@0+ (1,0) [0|8191] "mV" Vector__XXX
SG_ cellVoltage_207 m51 : 52|13@0+ (1,0) [0|8191] "mV" Vector__XXX
SG_ cellVoltage_208_invalidFlag m52 : 12|1@0+ (1,0) [0|1] "" Vector__XXX
SG_ cellVoltage_209_invalidFlag m52 : 13|1@0+ (1,0) [0|1] "" Vector__XXX
SG_ cellVoltage_210_invalidFlag m52 : 14|1@0+ (1,0) [0|1] "" Vector__XXX
SG_ cellVoltage_211_invalidFlag m52 : 15|1@0+ (1,0) [0|1] "" Vector__XXX
SG_ cellVoltage_208 m52 : 11|13@0+ (1,0) [0|8191] "mV" Vector__XXX
SG_ cellVoltage_209 m52 : 30|13@0+ (1,0) [0|8191] "mV" Vector__XXX
SG_ cellVoltage_210 m52 : 33|13@0+ (1,0) [0|8191] "mV" Vector__XXX
SG_ cellVoltage_211 m52 : 52|13@0+ (1,0) [0|8191] "mV" Vector__XXX
SG_ cellVoltage_212_invalidFlag m53 : 12|1@0+ (1,0) [0|1] "" Vector__XXX
SG_ cellVoltage_213_invalidFlag m53 : 13|1@0+ (1,0) [0|1] "" Vector__XXX
SG_ cellVoltage_214_invalidFlag m53 : 14|1@0+ (1,0) [0|1] "" Vector__XXX
SG_ cellVoltage_215_invalidFlag m53 : 15|1@0+ (1,0) [0|1] "" Vector__XXX
SG_ cellVoltage_212 m53 : 11|13@0+ (1,0) [0|8191] "mV" Vector__XXX
SG_ cellVoltage_213 m53 : 30|13@0+ (1,0) [0|8191] "mV" Vector__XXX
SG_ cellVoltage_214 m53 : 33|13@0+ (1,0) [0|8191] "mV" Vector__XXX
SG_ cellVoltage_215 m53 : 52|13@0+ (1,0) [0|8191] "mV" Vector__XXX

BO_ 592 foxBMS_CellTemperatures: 8 Vector__XXX
SG_ foxBMS_CellTemperatures_Mux M : 7|8@0+ (1,0) [0|0] "" Vector__XXX
SG_ cellTemperature_000_invalidFlag m0 : 8|1@0+ (1,0) [0|1] "" Vector__XXX
SG_ cellTemperature_001_invalidFlag m0 : 9|1@0+ (1,0) [0|1] "" Vector__XXX
SG_ cellTemperature_002_invalidFlag m0 : 10|1@0+ (1,0) [0|1] "" Vector__XXX
SG_ cellTemperature_003_invalidFlag m0 : 11|1@0+ (1,0) [0|1] "" Vector__XXX
SG_ cellTemperature_004_invalidFlag m0 : 12|1@0+ (1,0) [0|1] "" Vector__XXX
SG_ cellTemperature_005_invalidFlag m0 : 13|1@0+ (1,0) [0|1] "" Vector__XXX
SG_ cellTemperature_000 m0 : 23|8@0- (1,0) [-128|127] "degC" Vector__XXX
SG_ cellTemperature_001 m0 : 31|8@0- (1,0) [-128|127] "degC" Vector__XXX
SG_ cellTemperature_002 m0 : 39|8@0- (1,0) [-128|127] "degC" Vector__XXX
SG_ cellTemperature_003 m0 : 47|8@0- (1,0) [-128|127] "degC" Vector__XXX
SG_ cellTemperature_004 m0 : 55|8@0- (1,0) [-128|127] "degC" Vector__XXX
SG_ cellTemperature_005 m0 : 63|8@0- (1,0) [-128|127] "degC" Vector__XXX
SG_ cellTemperature_006_invalidFlag m1 : 8|1@0+ (1,0) [0|1] "" Vector__XXX
SG_ cellTemperature_007_invalidFlag m1 : 9|1@0+ (1,0) [0|1] "" Vector__XXX
SG_ cellTemperature_008_invalidFlag m1 : 10|1@0+ (1,0) [0|1] "" Vector__XXX
SG_ cellTemperature_009_invalidFlag m1 : 11|1@0+ (1,0) [0|1] "" Vector__XXX
SG_ cellTemperature_010_invalidFlag m1 : 12|1@0+ (1,0) [0|1] "" Vector__XXX
SG_ cellTemperature_011_invalidFlag m1 : 13|1@0+ (1,0) [0|1] "" Vector__XXX
SG_ cellTemperature_006 m1 : 23|8@0- (1,0) [-128|127] "degC" Vector__XXX
SG_ cellTemperature_007 m1 : 31|8@0- (1,0) [-128|127] "degC" Vector__XXX
SG_ cellTemperature_008 m1 : 39|8@0- (1,0) [-128|127] "degC" Vector__XXX
SG_ cellTemperature_009 m1 : 47|8@0- (1,0) [-128|127] "degC" Vector__XXX
SG_ cellTemperature_010 m1 : 55|8@0- (1,0) [-128|127] "degC" Vector__XXX
SG_ cellTemperature_011 m1 : 63|8@0- (1,0) [-128|127] "degC" Vector__XXX
SG_ cellTemperature_012_invalidFlag m2 : 8|1@0+ (1,0) [0|1] "" Vector__XXX
SG_ cellTemperature_013_invalidFlag m2 : 9|1@0+ (1,0) [0|1] "" Vector__XXX
SG_ cellTemperature_014_invalidFlag m2 : 10|1@0+ (1,0) [0|1] "" Vector__XXX
SG_ cellTemperature_015_invalidFlag m2 : 11|1@0+ (1,0) [0|1] "" Vector__XXX
SG_ cellTemperature_016_invalidFlag m2 : 12|1@0+ (1,0) [0|1] "" Vector__XXX
SG_ cellTemperature_017_invalidFlag m2 : 13|1@0+ (1,0) [0|1] "" Vector__XXX
SG_ cellTemperature_012 m2 : 23|8@0- (1,0) [-128|127] "degC" Vector__XXX
SG_ cellTemperature_013 m2 : 31|8@0- (1,0) [-128|127] "degC" Vector__XXX
SG_ cellTemperature_014 m2 : 39|8@0- (1,0) [-128|127] "degC" Vector__XXX
SG_ cellTemperature_015 m2 : 47|8@0- (1,0) [-128|127] "degC" Vector__XXX
SG_ cellTemperature_016 m2 : 55|8@0- (1,0) [-128|127] "degC" Vector__XXX
SG_ cellTemperature_017 m2 : 63|8@0- (1,0) [-128|127] "degC" Vector__XXX
SG_ cellTemperature_018_invalidFlag m3 : 8|1@0+ (1,0) [0|1] "" Vector__XXX
SG_ cellTemperature_019_invalidFlag m3 : 9|1@0+ (1,0) [0|1] "" Vector__XXX
SG_ cellTemperature_020_invalidFlag m3 : 10|1@0+ (1,0) [0|1] "" Vector__XXX
SG_ cellTemperature_021_invalidFlag m3 : 11|1@0+ (1,0) [0|1] "" Vector__XXX
SG_ cellTemperature_022_invalidFlag m3 : 12|1@0+ (1,0) [0|1] "" Vector__XXX
SG_ cellTemperature_023_invalidFlag m3 : 13|1@0+ (1,0) [0|1] "" Vector__XXX
SG_ cellTemperature_018 m3 : 23|8@0- (1,0) [-128|127] "degC" Vector__XXX
SG_ cellTemperature_019 m3 : 31|8@0- (1,0) [-128|127] "degC" Vector__XXX
SG_ cellTemperature_020 m3 : 39|8@0- (1,0) [-128|127] "degC" Vector__XXX
SG_ cellTemperature_021 m3 : 47|8@0- (1,0) [-128|127] "degC" Vector__XXX
SG_ cellTemperature_022 m3 : 55|8@0- (1,0) [-128|127] "degC" Vector__XXX
SG_ cellTemperature_023 m3 : 63|8@0- (1,0) [-128|127] "degC" Vector__XXX
SG_ cellTemperature_024_invalidFlag m4 : 8|1@0+ (1,0) [0|1] "" Vector__XXX
SG_ cellTemperature_025_invalidFlag m4 : 9|1@0+ (1,0) [0|1] "" Vector__XXX
SG_ cellTemperature_026_invalidFlag m4 : 10|1@0+ (1,0) [0|1] "" Vector__XXX
SG_ cellTemperature_027_invalidFlag m4 : 11|1@0+ (1,0) [0|1] "" Vector__XXX
SG_ cellTemperature_028_invalidFlag m4 : 12|1@0+ (1,0) [0|1] "" Vector__XXX
SG_ cellTemperature_029_invalidFlag m4 : 13|1@0+ (1,0) [0|1] "" Vector__XXX
SG_ cellTemperature_024 m4 : 23|8@0- (1,0) [-128|127] "degC" Vector__XXX
SG_ cellTemperature_025 m4 : 31|8@0- (1,0) [-128|127] "degC" Vector__XXX
SG_ cellTemperature_026 m4 : 39|8@0- (1,0) [-128|127] "degC" Vector__XXX
SG_ cellTemperature_027 m4 : 47|8@0- (1,0) [-128|127] "degC" Vector__XXX
SG_ cellTemperature_028 m4 : 55|8@0- (1,0) [-128|127] "degC" Vector__XXX
SG_ cellTemperature_029 m4 : 63|8@0- (1,0) [-128|127] "degC" Vector__XXX
SG_ cellTemperature_030_invalidFlag m5 : 8|1@0+ (1,0) [0|1] "" Vector__XXX
SG_ cellTemperature_031_invalidFlag m5 : 9|1@0+ (1,0) [0|1] "" Vector__XXX
SG_ cellTemperature_032_invalidFlag m5 : 10|1@0+ (1,0) [0|1] "" Vector__XXX
SG_ cellTemperature_033_invalidFlag m5 : 11|1@0+ (1,0) [0|1] "" Vector__XXX
SG_ cellTemperature_034_invalidFlag m5 : 12|1@0+ (1,0) [0|1] "" Vector__XXX
SG_ cellTemperature_035_invalidFlag m5 : 13|1@0+ (1,0) [0|1] "" Vector__XXX
SG_ cellTemperature_030 m5 : 23|8@0- (1,0) [-128|127] "degC" Vector__XXX
SG_ cellTemperature_031 m5 : 31|8@0- (1,0) [-128|127] "degC" Vector__XXX
SG_ cellTemperature_032 m5 : 39|8@0- (1,0) [-128|127] "degC" Vector__XXX
SG_ cellTemperature_033 m5 : 47|8@0- (1,0) [-128|127] "degC" Vector__XXX
SG_ cellTemperature_034 m5 : 55|8@0- (1,0) [-128|127] "degC" Vector__XXX
SG_ cellTemperature_035 m5 : 63|8@0- (1,0) [-128|127] "degC" Vector__XXX
SG_ cellTemperature_036_invalidFlag m6 : 8|1@0+ (1,0) [0|1] "" Vector__XXX
SG_ cellTemperature_037_invalidFlag m6 : 9|1@0+ (1,0) [0|1] "" Vector__XXX
SG_ cellTemperature_038_invalidFlag m6 : 10|1@0+ (1,0) [0|1] "" Vector__XXX
SG_ cellTemperature_039_invalidFlag m6 : 11|1@0+ (1,0) [0|1] "" Vector__XXX
SG_ cellTemperature_040_invalidFlag m6 : 12|1@0+ (1,0) [0|1] "" Vector__XXX
SG_ cellTemperature_041_invalidFlag m6 : 13|1@0+ (1,0) [0|1] "" Vector__XXX
SG_ cellTemperature_036 m6 : 23|8@0- (1,0) [-128|127] "degC" Vector__XXX
SG_ cellTemperature_037 m6 : 31|8@0- (1,0) [-128|127] "degC" Vector__XXX
SG_ cellTemperature_038 m6 : 39|8@0- (1,0) [-128|127] "degC" Vector__XXX
SG_ cellTemperature_039 m6 : 47|8@0- (1,0) [-128|127] "degC" Vector__XXX
SG_ cellTemperature_040 m6 : 55|8@0- (1,0) [-128|127] "degC" Vector__XXX
SG_ cellTemperature_041 m6 : 63|8@0- (1,0) [-128|127] "degC" Vector__XXX
SG_ cellTemperature_042_invalidFlag m7 : 8|1@0+ (1,0) [0|1] "" Vector__XXX
SG_ cellTemperature_043_invalidFlag m7 : 9|1@0+ (1,0) [0|1] "" Vector__XXX
SG_ cellTemperature_044_invalidFlag m7 : 10|1@0+ (1,0) [0|1] "" Vector__XXX
SG_ cellTemperature_045_invalidFlag m7 : 11|1@0+ (1,0) [0|1] "" Vector__XXX
SG_ cellTemperature_046_invalidFlag m7 : 12|1@0+ (1,0) [0|1] "" Vector__XXX
SG_ cellTemperature_047_invalidFlag m7 : 13|1@0+ (1,0) [0|1] "" Vector__XXX
SG_ cellTemperature_042 m7 : 23|8@0- (1,0) [-128|127] "degC" Vector__XXX
SG_ cellTemperature_043 m7 : 31|8@0- (1,0) [-128|127] "degC" Vector__XXX
SG_ cellTemperature_044 m7 : 39|8@0- (1,0) [-128|127] "degC" Vector__XXX
SG_ cellTemperature_045 m7 : 47|8@0- (1,0) [-128|127] "degC" Vector__XXX
SG_ cellTemperature_046 m7 : 55|8@0- (1,0) [-128|127] "degC" Vector__XXX
SG_ cellTemperature_047 m7 : 63|8@0- (1,0) [-128|127] "degC" Vector__XXX
SG_ cellTemperature_048_invalidFlag m8 : 8|1@0+ (1,0) [0|1] "" Vector__XXX
SG_ cellTemperature_049_invalidFlag m8 : 9|1@0+ (1,0) [0|1] "" Vector__XXX
SG_ cellTemperature_050_invalidFlag m8 : 10|1@0+ (1,0) [0|1] "" Vector__XXX
SG_ cellTemperature_051_invalidFlag m8 : 11|1@0+ (1,0) [0|1] "" Vector__XXX
SG_ cellTemperature_052_invalidFlag m8 : 12|1@0+ (1,0) [0|1] "" Vector__XXX
SG_ cellTemperature_053_invalidFlag m8 : 13|1@0+ (1,0) [0|1] "" Vector__XXX
SG_ cellTemperature_048 m8 : 23|8@0- (1,0) [-128|127] "degC" Vector__XXX
SG_ cellTemperature_049 m8 : 31|8@0- (1,0) [-128|127] "degC" Vector__XXX
SG_ cellTemperature_050 m8 : 39|8@0- (1,0) [-128|127] "degC" Vector__XXX
SG_ cellTemperature_051 m8 : 47|8@0- (1,0) [-128|127] "degC" Vector__XXX
SG_ cellTemperature_052 m8 : 55|8@0- (1,0) [-128|127] "degC" Vector__XXX
SG_ cellTemperature_053 m8 : 63|8@0- (1,0) [-128|127] "degC" Vector__XXX
SG_ cellTemperature_054_invalidFlag m9 : 8|1@0+ (1,0) [0|1] "" Vector__XXX
SG_ cellTemperature_055_invalidFlag m9 : 9|1@0+ (1,0) [0|1] "" Vector__XXX
SG_ cellTemperature_056_invalidFlag m9 : 10|1@0+ (1,0) [0|1] "" Vector__XXX
SG_ cellTemperature_057_invalidFlag m9 : 11|1@0+ (1,0) [0|1] "" Vector__XXX
SG_ cellTemperature_058_invalidFlag m9 : 12|1@0+ (1,0) [0|1] "" Vector__XXX
SG_ cellTemperature_059_invalidFlag m9 : 13|1@0+ (1,0) [0|1] "" Vector__XXX
SG_ cellTemperature_054 m9 : 23|8@0- (1,0) [-128|127] "degC" Vector__XXX
SG_ cellTemperature_055 m9 : 31|8@0- (1,0) [-128|127] "degC" Vector__XXX
SG_ cellTemperature_056 m9 : 39|8@0- (1,0) [-128|127] "degC" Vector__XXX
SG_ cellTemperature_057 m9 : 47|8@0- (1,0) [-128|127] "degC" Vector__XXX
SG_ cellTemperature_058 m9 : 55|8@0- (1,0) [-128|127] "degC" Vector__XXX
SG_ cellTemperature_059 m9 : 63|8@0- (1,0) [-128|127] "degC" Vector__XXX
SG_ cellTemperature_060_invalidFlag m10 : 8|1@0+ (1,0) [0|1] "" Vector__XXX
SG_ cellTemperature_061_invalidFlag m10 : 9|1@0+ (1,0) [0|1] "" Vector__XXX
SG_ cellTemperature_062_invalidFlag m10 : 10|1@0+ (1,0) [0|1] "" Vector__XXX
SG_ cellTemperature_063_invalidFlag m10 : 11|1@0+ (1,0) [0|1] "" Vector__XXX
SG_ cellTemperature_064_invalidFlag m10 : 12|1@0+ (1,0) [0|1] "" Vector__XXX
SG_ cellTemperature_065_invalidFlag m10 : 13|1@0+ (1,0) [0|1] "" Vector__XXX
SG_ cellTemperature_060 m10 : 23|8@0- (1,0) [-128|127] "degC" Vector__XXX
SG_ cellTemperature_061 m10 : 31|8@0- (1,0) [-128|127] "degC" Vector__XXX
SG_ cellTemperature_062 m10 : 39|8@0- (1,0) [-128|127] "degC" Vector__XXX
SG_ cellTemperature_063 m10 : 47|8@0- (1,0) [-128|127] "degC" Vector__XXX
SG_ cellTemperature_064 m10 : 55|8@0- (1,0) [-128|127] "degC" Vector__XXX
SG_ cellTemperature_065 m10 : 63|8@0- (1,0) [-128|127] "degC" Vector__XXX
SG_ cellTemperature_066_invalidFlag m11 : 8|1@0+ (1,0) [0|1] "" Vector__XXX
SG_ cellTemperature_067_invalidFlag m11 : 9|1@0+ (1,0) [0|1] "" Vector__XXX
SG_ cellTemperature_068_invalidFlag m11 : 10|1@0+ (1,0) [0|1] "" Vector__XXX
SG_ cellTemperature_069_invalidFlag m11 : 11|1@0+ (1,0) [0|1] "" Vector__XXX
SG_ cellTemperature_070_invalidFlag m11 : 12|1@0+ (1,0) [0|1] "" Vector__XXX
SG_ cellTemperature_071_invalidFlag m11 : 13|1@0+ (1,0) [0|1] "" Vector__XXX
SG_ cellTemperature_066 m11 : 23|8@0- (1,0) [-128|127] "degC" Vector__XXX
SG_ cellTemperature_067 m11 : 31|8@0- (1,0) [-128|127] "degC" Vector__XXX
SG_ cellTemperature_068 m11 : 39|8@0- (1,0) [-128|127] "degC" Vector__XXX
SG_ cellTemperature_069 m11 : 47|8@0- (1,0) [-128|127] "degC" Vector__XXX
SG_ cellTemperature_070 m11 : 55|8@0- (1,0) [-128|127] "degC" Vector__XXX
SG_ cellTemperature_071 m11 : 63|8@0- (1,0) [-128|127] "degC" Vector__XXX
SG_ cellTemperature_072_invalidFlag m12 : 8|1@0+ (1,0) [0|1] "" Vector__XXX
SG_ cellTemperature_073_invalidFlag m12 : 9|1@0+ (1,0) [0|1] "" Vector__XXX
SG_ cellTemperature_074_invalidFlag m12 : 10|1@0+ (1,0) [0|1] "" Vector__XXX
SG_ cellTemperature_075_invalidFlag m12 : 11|1@0+ (1,0) [0|1] "" Vector__XXX
SG_ cellTemperature_076_invalidFlag m12 : 12|1@0+ (1,0) [0|1] "" Vector__XXX
SG_ cellTemperature_077_invalidFlag m12 : 13|1@0+ (1,0) [0|1] "" Vector__XXX
SG_ cellTemperature_072 m12 : 23|8@0- (1,0) [-128|127] "degC" Vector__XXX
SG_ cellTemperature_073 m12 : 31|8@0- (1,0) [-128|127] "degC" Vector__XXX
SG_ cellTemperature_074 m12 : 39|8@0- (1,0) [-128|127] "degC" Vector__XXX
SG_ cellTemperature_075 m12 : 47|8@0- (1,0) [-128|127] "degC" Vector__XXX
SG_ cellTemperature_076 m12 : 55|8@0- (1,0) [-128|127] "degC" Vector__XXX
SG_ cellTemperature_077 m12 : 63|8@0- (1,0) [-128|127] "degC" Vector__XXX
SG_ cellTemperature_078_invalidFlag m13 : 8|1@0+ (1,0) [0|1] "" Vector__XXX
SG_ cellTemperature_079_invalidFlag m13 : 9|1@0+ (1,0) [0|1] "" Vector__XXX
SG_ cellTemperature_080_invalidFlag m13 : 10|1@0+ (1,0) [0|1] "" Vector__XXX
SG_ cellTemperature_081_invalidFlag m13 : 11|1@0+ (1,0) [0|1] "" Vector__XXX
SG_ cellTemperature_082_invalidFlag m13 : 12|1@0+ (1,0) [0|1] "" Vector__XXX
SG_ cellTemperature_083_invalidFlag m13 : 13|1@0+ (1,0) [0|1] "" Vector__XXX
SG_ cellTemperature_078 m13 : 23|8@0- (1,0) [-128|127] "degC" Vector__XXX
SG_ cellTemperature_079 m13 : 31|8@0- (1,0) [-128|127] "degC" Vector__XXX
SG_ cellTemperature_080 m13 : 39|8@0- (1,0) [-128|127] "degC" Vector__XXX
SG_ cellTemperature_081 m13 : 47|8@0- (1,0) [-128|127] "degC" Vector__XXX
SG_ cellTemperature_082 m13 : 55|8@0- (1,0) [-128|127] "degC" Vector__XXX
SG_ cellTemperature_083 m13 : 63|8@0- (1,0) [-128|127] "degC" Vector__XXX
SG_ cellTemperature_084_invalidFlag m14 : 8|1@0+ (1,0) [0|1] "" Vector__XXX
SG_ cellTemperature_085_invalidFlag m14 : 9|1@0+ (1,0) [0|1] "" Vector__XXX
SG_ cellTemperature_086_invalidFlag m14 : 10|1@0+ (1,0) [0|1] "" Vector__XXX
SG_ cellTemperature_087_invalidFlag m14 : 11|1@0+ (1,0) [0|1] "" Vector__XXX
SG_ cellTemperature_088_invalidFlag m14 : 12|1@0+ (1,0) [0|1] "" Vector__XXX
SG_ cellTemperature_089_invalidFlag m14 : 13|1@0+ (1,0) [0|1] "" Vector__XXX
SG_ cellTemperature_084 m14 : 23|8@0- (1,0) [-128|127] "degC" Vector__XXX
SG_ cellTemperature_085 m14 : 31|8@0- (1,0) [-128|127] "degC" Vector__XXX
SG_ cellTemperature_086 m14 : 39|8@0- (1,0) [-128|127] "degC" Vector__XXX
SG_ cellTemperature_087 m14 : 47|8@0- (1,0) [-128|127] "degC" Vector__XXX
SG_ cellTemperature_088 m14 : 55|8@0- (1,0) [-128|127] "degC" Vector__XXX
SG_ cellTemperature_089 m14 : 63|8@0- (1,0) [-128|127] "degC" Vector__XXX
SG_ cellTemperature_090_invalidFlag m15 : 8|1@0+ (1,0) [0|1] "" Vector__XXX
SG_ cellTemperature_091_invalidFlag m15 : 9|1@0+ (1,0) [0|1] "" Vector__XXX
SG_ cellTemperature_092_invalidFlag m15 : 10|1@0+ (1,0) [0|1] "" Vector__XXX
SG_ cellTemperature_093_invalidFlag m15 : 11|1@0+ (1,0) [0|1] "" Vector__XXX
SG_ cellTemperature_094_invalidFlag m15 : 12|1@0+ (1,0) [0|1] "" Vector__XXX
SG_ cellTemperature_095_invalidFlag m15 : 13|1@0+ (1,0) [0|1] "" Vector__XXX
SG_ cellTemperature_090 m15 : 23|8@0- (1,0) [-128|127] "degC" Vector__XXX
SG_ cellTemperature_091 m15 : 31|8@0- (1,0) [-128|127] "degC" Vector__XXX
SG_ cellTemperature_092 m15 : 39|8@0- (1,0) [-128|127] "degC" Vector__XXX
SG_ cellTemperature_093 m15 : 47|8@0- (1,0) [-128|127] "degC" Vector__XXX
SG_ cellTemperature_094 m15 : 55|8@0- (1,0) [-128|127] "degC" Vector__XXX
SG_ cellTemperature_095 m15 : 63|8@0- (1,0) [-128|127] "degC" Vector__XXX
SG_ cellTemperature_096_invalidFlag m16 : 8|1@0+ (1,0) [0|1] "" Vector__XXX
SG_ cellTemperature_097_invalidFlag m16 : 9|1@0+ (1,0) [0|1] "" Vector__XXX
SG_ cellTemperature_098_invalidFlag m16 : 10|1@0+ (1,0) [0|1] "" Vector__XXX
SG_ cellTemperature_099_invalidFlag m16 : 11|1@0+ (1,0) [0|1] "" Vector__XXX
SG_ cellTemperature_100_invalidFlag m16 : 12|1@0+ (1,0) [0|1] "" Vector__XXX
SG_ cellTemperature_101_invalidFlag m16 : 13|1@0+ (1,0) [0|1] "" Vector__XXX
SG_ cellTemperature_096 m16 : 23|8@0- (1,0) [-128|127] "degC" Vector__XXX
SG_ cellTemperature_097 m16 : 31|8@0- (1,0) [-128|127] "degC" Vector__XXX
SG_ cellTemperature_098 m16 : 39|8@0- (1,0) [-128|127] "degC" Vector__XXX
SG_ cellTemperature_099 m16 : 47|8@0- (1,0) [-128|127] "degC" Vector__XXX
SG_ cellTemperature_100 m16 : 55|8@0- (1,0) [-128|127] "degC" Vector__XXX
SG_ cellTemperature_101 m16 : 63|8@0- (1,0) [-128|127] "degC" Vector__XXX
SG_ cellTemperature_102_invalidFlag m17 : 8|1@0+ (1,0) [0|1] "" Vector__XXX
SG_ cellTemperature_103_invalidFlag m17 : 9|1@0+ (1,0) [0|1] "" Vector__XXX
SG_ cellTemperature_104_invalidFlag m17 : 10|1@0+ (1,0) [0|1] "" Vector__XXX
SG_ cellTemperature_105_invalidFlag m17 : 11|1@0+ (1,0) [0|1] "" Vector__XXX
SG_ cellTemperature_106_invalidFlag m17 : 12|1@0+ (1,0) [0|1] "" Vector__XXX
SG_ cellTemperature_107_invalidFlag m17 : 13|1@0+ (1,0) [0|1] "" Vector__XXX
SG_ cellTemperature_102 m17 : 23|8@0- (1,0) [-128|127] "degC" Vector__XXX
SG_ cellTemperature_103 m17 : 31|8@0- (1,0) [-128|127] "degC" Vector__XXX
SG_ cellTemperature_104 m17 : 39|8@0- (1,0) [-128|127] "degC" Vector__XXX
SG_ cellTemperature_105 m17 : 47|8@0- (1,0) [-128|127] "degC" Vector__XXX
SG_ cellTemperature_106 m17 : 55|8@0- (1,0) [-128|127] "degC" Vector__XXX
SG_ cellTemperature_107 m17 : 63|8@0- (1,0) [-128|127] "degC" Vector__XXX
SG_ cellTemperature_108_invalidFlag m18 : 8|1@0+ (1,0) [0|1] "" Vector__XXX
SG_ cellTemperature_109_invalidFlag m18 : 9|1@0+ (1,0) [0|1] "" Vector__XXX
SG_ cellTemperature_110_invalidFlag m18 : 10|1@0+ (1,0) [0|1] "" Vector__XXX
SG_ cellTemperature_111_invalidFlag m18 : 11|1@0+ (1,0) [0|1] "" Vector__XXX
SG_ cellTemperature_112_invalidFlag m18 : 12|1@0+ (1,0) [0|1] "" Vector__XXX
SG_ cellTemperature_113_invalidFlag m18 : 13|1@0+ (1,0) [0|1] "" Vector__XXX
SG_ cellTemperature_108 m18 : 23|8@0- (1,0) [-128|127] "degC" Vector__XXX
SG_ cellTemperature_109 m18 : 31|8@0- (1,0) [-128|127] "degC" Vector__XXX
SG_ cellTemperature_110 m18 : 39|8@0- (1,0) [-128|127] "degC" Vector__XXX
SG_ cellTemperature_111 m18 : 47|8@0- (1,0) [-128|127] "degC" Vector__XXX
SG_ cellTemperature_112 m18 : 55|8@0- (1,0) [-128|127] "degC" Vector__XXX
SG_ cellTemperature_113 m18 : 63|8@0- (1,0) [-128|127] "degC" Vector__XXX
SG_ cellTemperature_114_invalidFlag m19 : 8|1@0+ (1,0) [0|1] "" Vector__XXX
SG_ cellTemperature_115_invalidFlag m19 : 9|1@0+ (1,0) [0|1] "" Vector__XXX
SG_ cellTemperature_116_invalidFlag m19 : 10|1@0+ (1,0) [0|1] "" Vector__XXX
SG_ cellTemperature_117_invalidFlag m19 : 11|1@0+ (1,0) [0|1] "" Vector__XXX
SG_ cellTemperature_118_invalidFlag m19 : 12|1@0+ (1,0) [0|1] "" Vector__XXX
SG_ cellTemperature_119_invalidFlag m19 : 13|1@0+ (1,0) [0|1] "" Vector__XXX
SG_ cellTemperature_114 m19 : 23|8@0- (1,0) [-128|127] "degC" Vector__XXX
SG_ cellTemperature_115 m19 : 31|8@0- (1,0) [-128|127] "degC" Vector__XXX
SG_ cellTemperature_116 m19 : 39|8@0- (1,0) [-128|127] "degC" Vector__XXX
SG_ cellTemperature_117 m19 : 47|8@0- (1,0) [-128|127] "degC" Vector__XXX
SG_ cellTemperature_118 m19 : 55|8@0- (1,0) [-128|127] "degC" Vector__XXX
SG_ cellTemperature_119 m19 : 63|8@0- (1,0) [-128|127] "degC" Vector__XXX
SG_ cellTemperature_120_invalidFlag m20 : 8|1@0+ (1,0) [0|1] "" Vector__XXX
SG_ cellTemperature_121_invalidFlag m20 : 9|1@0+ (1,0) [0|1] "" Vector__XXX
SG_ cellTemperature_122_invalidFlag m20 : 10|1@0+ (1,0) [0|1] "" Vector__XXX
SG_ cellTemperature_123_invalidFlag m20 : 11|1@0+ (1,0) [0|1] "" Vector__XXX
SG_ cellTemperature_124_invalidFlag m20 : 12|1@0+ (1,0) [0|1] "" Vector__XXX
SG_ cellTemperature_125_invalidFlag m20 : 13|1@0+ (1,0) [0|1] "" Vector__XXX
SG_ cellTemperature_120 m20 : 23|8@0- (1,0) [-128|127] "degC" Vector__XXX
SG_ cellTemperature_121 m20 : 31|8@0- (1,0) [-128|127] "degC" Vector__XXX
SG_ cellTemperature_122 m20 : 39|8@0- (1,0) [-128|127] "degC" Vector__XXX
SG_ cellTemperature_123 m20 : 47|8@0- (1,0) [-128|127] "degC" Vector__XXX
SG_ cellTemperature_124 m20 : 55|8@0- (1,0) [-128|127] "degC" Vector__XXX
SG_ cellTemperature_125 m20 : 63|8@0- (1,0) [-128|127] "degC" Vector__XXX
SG_ cellTemperature_126_invalidFlag m21 : 8|1@0+ (1,0) [0|1] "" Vector__XXX
SG_ cellTemperature_127_invalidFlag m21 : 9|1@0+ (1,0) [0|1] "" Vector__XXX
SG_ cellTemperature_128_invalidFlag m21 : 10|1@0+ (1,0) [0|1] "" Vector__XXX
SG_ cellTemperature_129_invalidFlag m21 : 11|1@0+ (1,0) [0|1] "" Vector__XXX
SG_ cellTemperature_130_invalidFlag m21 : 12|1@0+ (1,0) [0|1] "" Vector__XXX
SG_ cellTemperature_131_invalidFlag m21 : 13|1@0+ (1,0) [0|1] "" Vector__XXX
SG_ cellTemperature_126 m21 : 23|8@0- (1,0) [-128|127] "degC" Vector__XXX
SG_ cellTemperature_127 m21 : 31|8@0- (1,0) [-128|127] "degC" Vector__XXX
SG_ cellTemperature_128 m21 : 39|8@0- (1,0) [-128|127] "degC" Vector__XXX
SG_ cellTemperature_129 m21 : 47|8@0- (1,0) [-128|127] "degC" Vector__XXX
SG_ cellTemperature_130 m21 : 55|8@0- (1,0) [-128|127] "degC" Vector__XXX
SG_ cellTemperature_131 m21 : 63|8@0- (1,0) [-128|127] "degC" Vector__XXX
SG_ cellTemperature_132_invalidFlag m22 : 8|1@0+ (1,0) [0|1] "" Vector__XXX
SG_ cellTemperature_133_invalidFlag m22 : 9|1@0+ (1,0) [0|1] "" Vector__XXX
SG_ cellTemperature_134_invalidFlag m22 : 10|1@0+ (1,0) [0|1] "" Vector__XXX
SG_ cellTemperature_135_invalidFlag m22 : 11|1@0+ (1,0) [0|1] "" Vector__XXX
SG_ cellTemperature_136_invalidFlag m22 : 12|1@0+ (1,0) [0|1] "" Vector__XXX
SG_ cellTemperature_137_invalidFlag m22 : 13|1@0+ (1,0) [0|1] "" Vector__XXX
SG_ cellTemperature_132 m22 : 23|8@0- (1,0) [-128|127] "degC" Vector__XXX
SG_ cellTemperature_133 m22 : 31|8@0- (1,0) [-128|127] "degC" Vector__XXX
SG_ cellTemperature_134 m22 : 39|8@0- (1,0) [-128|127] "degC" Vector__XXX
SG_ cellTemperature_135 m22 : 47|8@0- (1,0) [-128|127] "degC" Vector__XXX
SG_ cellTemperature_136 m22 : 55|8@0- (1,0) [-128|127] "degC" Vector__XXX
SG_ cellTemperature_137 m22 : 63|8@0- (1,0) [-128|127] "degC" Vector__XXX
SG_ cellTemperature_138_invalidFlag m23 : 8|1@0+ (1,0) [0|1] "" Vector__XXX
SG_ cellTemperature_139_invalidFlag m23 : 9|1@0+ (1,0) [0|1] "" Vector__XXX
SG_ cellTemperature_140_invalidFlag m23 : 10|1@0+ (1,0) [0|1] "" Vector__XXX
SG_ cellTemperature_141_invalidFlag m23 : 11|1@0+ (1,0) [0|1] "" Vector__XXX
SG_ cellTemperature_142_invalidFlag m23 : 12|1@0+ (1,0) [0|1] "" Vector__XXX
SG_ cellTemperature_143_invalidFlag m23 : 13|1@0+ (1,0) [0|1] "" Vector__XXX
SG_ cellTemperature_138 m23 : 23|8@0- (1,0) [-128|127] "degC" Vector__XXX
SG_ cellTemperature_139 m23 : 31|8@0- (1,0) [-128|127] "degC" Vector__XXX
SG_ cellTemperature_140 m23 : 39|8@0- (1,0) [-128|127] "degC" Vector__XXX
SG_ cellTemperature_141 m23 : 47|8@0- (1,0) [-128|127] "degC" Vector__XXX
SG_ cellTemperature_142 m23 : 55|8@0- (1,0) [-128|127] "degC" Vector__XXX
SG_ cellTemperature_143 m23 : 63|8@0- (1,0) [-128|127] "degC" Vector__XXX
SG_ cellTemperature_144_invalidFlag m24 : 8|1@0+ (1,0) [0|1] "" Vector__XXX
SG_ cellTemperature_145_invalidFlag m24 : 9|1@0+ (1,0) [0|1] "" Vector__XXX
SG_ cellTemperature_146_invalidFlag m24 : 10|1@0+ (1,0) [0|1] "" Vector__XXX
SG_ cellTemperature_147_invalidFlag m24 : 11|1@0+ (1,0) [0|1] "" Vector__XXX
SG_ cellTemperature_148_invalidFlag m24 : 12|1@0+ (1,0) [0|1] "" Vector__XXX
SG_ cellTemperature_149_invalidFlag m24 : 13|1@0+ (1,0) [0|1] "" Vector__XXX
SG_ cellTemperature_144 m24 : 23|8@0- (1,0) [-128|127] "degC" Vector__XXX
SG_ cellTemperature_145 m24 : 31|8@0- (1,0) [-128|127] "degC" Vector__XXX
SG_ cellTemperature_146 m24 : 39|8@0- (1,0) [-128|127] "degC" Vector__XXX
SG_ cellTemperature_147 m24 : 47|8@0- (1,0) [-128|127] "degC" Vector__XXX
SG_ cellTemperature_148 m24 : 55|8@0- (1,0) [-128|127] "degC" Vector__XXX
SG_ cellTemperature_149 m24 : 63|8@0- (1,0) [-128|127] "degC" Vector__XXX
SG_ cellTemperature_150_invalidFlag m25 : 8|1@0+ (1,0) [0|1] "" Vector__XXX
SG_ cellTemperature_151_invalidFlag m25 : 9|1@0+ (1,0) [0|1] "" Vector__XXX
SG_ cellTemperature_152_invalidFlag m25 : 10|1@0+ (1,0) [0|1] "" Vector__XXX
SG_ cellTemperature_153_invalidFlag m25 : 11|1@0+ (1,0) [0|1] "" Vector__XXX
SG_ cellTemperature_154_invalidFlag m25 : 12|1@0+ (1,0) [0|1] "" Vector__XXX
SG_ cellTemperature_155_invalidFlag m25 : 13|1@0+ (1,0) [0|1] "" Vector__XXX
SG_ cellTemperature_150 m25 : 23|8@0- (1,0) [-128|127] "degC" Vector__XXX
SG_ cellTemperature_151 m25 : 31|8@0- (1,0) [-128|127] "degC" Vector__XXX
SG_ cellTemperature_152 m25 : 39|8@0- (1,0) [-128|127] "degC" Vector__XXX
SG_ cellTemperature_153 m25 : 47|8@0- (1,0) [-128|127] "degC" Vector__XXX
SG_ cellTemperature_154 m25 : 55|8@0- (1,0) [-128|127] "degC" Vector__XXX
SG_ cellTemperature_155 m25 : 63|8@0- (1,0) [-128|127] "degC" Vector__XXX
SG_ cellTemperature_156_invalidFlag m26 : 8|1@0+ (1,0) [0|1] "" Vector__XXX
SG_ cellTemperature_157_invalidFlag m26 : 9|1@0+ (1,0) [0|1] "" Vector__XXX
SG_ cellTemperature_158_invalidFlag m26 : 10|1@0+ (1,0) [0|1] "" Vector__XXX
SG_ cellTemperature_159_invalidFlag m26 : 11|1@0+ (1,0) [0|1] "" Vector__XXX
SG_ cellTemperature_160_invalidFlag m26 : 12|1@0+ (1,0) [0|1] "" Vector__XXX
SG_ cellTemperature_161_invalidFlag m26 : 13|1@0+ (1,0) [0|1] "" Vector__XXX
SG_ cellTemperature_156 m26 : 23|8@0- (1,0) [-128|127] "degC" Vector__XXX
SG_ cellTemperature_157 m26 : 31|8@0- (1,0) [-128|127] "degC" Vector__XXX
SG_ cellTemperature_158 m26 : 39|8@0- (1,0) [-128|127] "degC" Vector__XXX
SG_ cellTemperature_159 m26 : 47|8@0- (1,0) [-128|127] "degC" Vector__XXX
SG_ cellTemperature_160 m26 : 55|8@0- (1,0) [-128|127] "degC" Vector__XXX
SG_ cellTemperature_161 m26 : 63|8@0- (1,0) [-128|127] "degC" Vector__XXX
SG_ cellTemperature_162_invalidFlag m27 : 8|1@0+ (1,0) [0|1] "" Vector__XXX
SG_ cellTemperature_163_invalidFlag m27 : 9|1@0+ (1,0) [0|1] "" Vector__XXX
SG_ cellTemperature_164_invalidFlag m27 : 10|1@0+ (1,0) [0|1] "" Vector__XXX
SG_ cellTemperature_165_invalidFlag m27 : 11|1@0+ (1,0) [0|1] "" Vector__XXX
SG_ cellTemperature_166_invalidFlag m27 : 12|1@0+ (1,0) [0|1] "" Vector__XXX
SG_ cellTemperature_167_invalidFlag m27 : 13|1@0+ (1,0) [0|1] "" Vector__XXX
SG_ cellTemperature_162 m27 : 23|8@0- (1,0) [-128|127] "degC" Vector__XXX
SG_ cellTemperature_163 m27 : 31|8@0- (1,0) [-128|127] "degC" Vector__XXX
SG_ cellTemperature_164 m27 : 39|8@0- (1,0) [-128|127] "degC" Vector__XXX
SG_ cellTemperature_165 m27 : 47|8@0- (1,0) [-128|127] "degC" Vector__XXX
SG_ cellTemperature_166 m27 : 55|8@0- (1,0) [-128|127] "degC" Vector__XXX
SG_ cellTemperature_167 m27 : 63|8@0- (1,0) [-128|127] "degC" Vector__XXX
SG_ cellTemperature_168_invalidFlag m28 : 8|1@0+ (1,0) [0|1] "" Vector__XXX
SG_ cellTemperature_169_invalidFlag m28 : 9|1@0+ (1,0) [0|1] "" Vector__XXX
SG_ cellTemperature_170_invalidFlag m28 : 10|1@0+ (1,0) [0|1] "" Vector__XXX
SG_ cellTemperature_171_invalidFlag m28 : 11|1@0+ (1,0) [0|1] "" Vector__XXX
SG_ cellTemperature_172_invalidFlag m28 : 12|1@0+ (1,0) [0|1] "" Vector__XXX
SG_ cellTemperature_173_invalidFlag m28 : 13|1@0+ (1,0) [0|1] "" Vector__XXX
SG_ cellTemperature_168 m28 : 23|8@0- (1,0) [-128|127] "degC" Vector__XXX
SG_ cellTemperature_169 m28 : 31|8@0- (1,0) [-128|127] "degC" Vector__XXX
SG_ cellTemperature_170 m28 : 39|8@0- (1,0) [-128|127] "degC" Vector__XXX
SG_ cellTemperature_171 m28 : 47|8@0- (1,0) [-128|127] "degC" Vector__XXX
SG_ cellTemperature_172 m28 : 55|8@0- (1,0) [-128|127] "degC" Vector__XXX
SG_ cellTemperature_173 m28 : 63|8@0- (1,0) [-128|127] "degC" Vector__XXX
SG_ cellTemperature_174_invalidFlag m29 : 8|1@0+ (1,0) [0|1] "" Vector__XXX
SG_ cellTemperature_175_invalidFlag m29 : 9|1@0+ (1,0) [0|1] "" Vector__XXX
SG_ cellTemperature_176_invalidFlag m29 : 10|1@0+ (1,0) [0|1] "" Vector__XXX
SG_ cellTemperature_177_invalidFlag m29 : 11|1@0+ (1,0) [0|1] "" Vector__XXX
SG_ cellTemperature_178_invalidFlag m29 : 12|1@0+ (1,0) [0|1] "" Vector__XXX
SG_ cellTemperature_179_invalidFlag m29 : 13|1@0+ (1,0) [0|1] "" Vector__XXX
SG_ cellTemperature_174 m29 : 23|8@0- (1,0) [-128|127] "degC" Vector__XXX
SG_ cellTemperature_175 m29 : 31|8@0- (1,0) [-128|127] "degC" Vector__XXX
SG_ cellTemperature_176 m29 : 39|8@0- (1,0) [-128|127] "degC" Vector__XXX
SG_ cellTemperature_177 m29 : 47|8@0- (1,0) [-128|127] "degC" Vector__XXX
SG_ cellTemperature_178 m29 : 55|8@0- (1,0) [-128|127] "degC" Vector__XXX
SG_ cellTemperature_179 m29 : 63|8@0- (1,0) [-128|127] "degC" Vector__XXX

BO_ 560 foxBMS_BmsStateRequest: 8 Vector__XXX
SG_ foxBMS_modeRequest : 1|2@0+ (1,0) [0|3] "" Vector__XXX
SG_ foxBMS_activateBalancing : 8|1@0+ (1,0) [0|1] "" Vector__XXX
SG_ foxBMS_balancingThreshold : 23|8@0+ (1,0) [0|255] "mV" Vector__XXX
SG_ foxBMS_externallyPrecharged : 3|1@0+ (1,0) [0|1] "" Vector__XXX
SG_ foxBMS_resetFlags : 2|1@0+ (1,0) [0|1] "" Vector__XXX
SG_ foxBMS_chargerConnected : 4|1@0+ (1,0) [0|1] "" Vector__XXX
SG_ foxBMS_disableInsulationMon : 5|1@0+ (1,0) [0|1] "" Vector__XXX
SG_ foxBMS_heaterOverride_ON : 6|1@0+ (1,0) [0|1] "" Vector__XXX
SG_ foxBMS_heaterOverride_OFF : 7|1@0+ (1,0) [0|1] "" Vector__XXX

BO_ 544 foxBMS_BmsState: 8 Vector__XXX
SG_ foxBMS_State : 3|4@0+ (1,0) [0|15] "" Vector__XXX
SG_ BMS_nrOfConnectedStrings : 7|4@0+ (1,0) [0|15] "" Vector__XXX
SG_ foxBMS_generalError : 10|1@0+ (1,0) [0|1] "" Vector__XXX
SG_ foxBMS_generalWarning : 9|1@0+ (1,0) [0|1] "" Vector__XXX
SG_ foxBMS_Error_dieTemperatureMCU : 18|1@0+ (1,0) [0|1] "" Vector__XXX
SG_ foxBMS_Error_OvertempPCB : 19|1@0+ (1,0) [0|1] "" Vector__XXX
SG_ foxBMS_Error_UndertempPCB : 20|1@0+ (1,0) [0|1] "" Vector__XXX
SG_ foxBMS_Error_PrechargeVolt : 16|1@0+ (1,0) [0|1] "" Vector__XXX
SG_ foxBMS_Error_PrechargeCurrent : 17|1@0+ (1,0) [0|1] "" Vector__XXX
SG_ foxBMS_heaterState : 14|1@0+ (1,0) [0|1] "" Vector__XXX
SG_ foxBMS_coolingState : 15|1@0+ (1,0) [0|1] "" Vector__XXX
SG_ foxBMS_insulationMonitoring : 13|1@0+ (1,0) [0|1] "" Vector__XXX
SG_ foxBMS_chargingComplete : 8|1@0+ (1,0) [0|1] "" Vector__XXX
SG_ foxBMS_EmergencyShutoff : 11|1@0+ (1,0) [0|1] "" Vector__XXX
SG_ foxBMS_MainFuseBlown : 21|1@0+ (1,0) [0|1] "" Vector__XXX
SG_ foxBMS_insulationResistance : 63|8@0+ (10,0) [0|2550] "kOhm" Vector__XXX
SG_ foxBMS_Error_Interlock : 22|1@0+ (1,0) [0|1] "" Vector__XXX
SG_ foxBMS_NrDeactivatedStrings : 51|4@0+ (1,0) [0|15] "" Vector__XXX
SG_ foxBMS_Error_Insulation : 23|1@0+ (1,0) [0|1] "" Vector__XXX
SG_ foxBMS_Error_Cantiming : 24|1@0+ (1,0) [0|1] "" Vector__XXX
SG_ foxBMS_Error_PackOvercurr_Charge : 25|1@0+ (1,0) [0|1] "" Vector__XXX
SG_ foxBMS_Error_PackOvercur_Dischrg : 26|1@0+ (1,0) [0|1] "" Vector__XXX
SG_ foxBMS_SysMonError : 12|1@0+ (1,0) [0|1] "" Vector__XXX
SG_ foxBMS_alertFlag : 27|1@0+ (1,0) [0|1] "" Vector__XXX
SG_ foxBMS_NvramCrcError : 28|1@0+ (1,0) [0|1] "" Vector__XXX

BO_ 545 foxBMS_StringState: 8 Vector__XXX
SG_ foxBMS_StringState_Mux M : 3|4@0+ (1,0) [0|0] "" Vector__XXX
SG_ String0_stringConnected : 4|1@0+ (1,0) [0|1] "" Vector__XXX
SG_ String0_balancing_active : 5|1@0+ (1,0) [0|1] "" Vector__XXX
SG_ String0_Err_overtemp_charge : 8|1@0+ (1,0) [0|1] "" Vector__XXX
SG_ String0_Err_undertemp_charge : 9|1@0+ (1,0) [0|1] "" Vector__XXX
SG_ String0_Err_overtemp_discharge : 10|1@0+ (1,0) [0|1] "" Vector__XXX
SG_ String0_Err_undertemp_discharge : 11|1@0+ (1,0) [0|1] "" Vector__XXX
SG_ String0_Err_Overcurrent_charge : 12|1@0+ (1,0) [0|1] "" Vector__XXX
SG_ String0_Err_Overcurre_discharge : 13|1@0+ (1,0) [0|1] "" Vector__XXX
SG_ String0_Err_Overvoltage : 14|1@0+ (1,0) [0|1] "" Vector__XXX
SG_ String0_Err_Undervoltage : 15|1@0+ (1,0) [0|1] "" Vector__XXX
SG_ String0_Err_deep_discharge : 7|1@0+ (1,0) [0|1] "" Vector__XXX
SG_ String0_Err_CS_currentMeas : 43|1@0+ (1,0) [0|1] "" Vector__XXX
SG_ String0_Err_positiveContactor : 32|1@0+ (1,0) [0|1] "" Vector__XXX
SG_ String0_Err_openWire : 49|1@0+ (1,0) [0|1] "" Vector__XXX
SG_ String0_openWireNumber : 63|8@0+ (1,0) [0|255] "" Vector__XXX
SG_ String0_Err_plaus_cell_volt : 52|1@0+ (1,0) [0|1] "" Vector__XXX
SG_ String0_Err_plaus_cell_temp : 51|1@0+ (1,0) [0|1] "" Vector__XXX
SG_ String0_Err_plaus_string_volt : 53|1@0+ (1,0) [0|1] "" Vector__XXX
SG_ String0_Err_slave_hardware : 34|1@0+ (1,0) [0|1] "" Vector__XXX
SG_ String0_Err_dsyChainBase_Comm : 35|1@0+ (1,0) [0|1] "" Vector__XXX
SG_ String0_Err_dsyChainPrim_CRC : 37|1@0+ (1,0) [0|1] "" Vector__XXX
SG_ String0_Err_dsyChainRedun_Comm : 36|1@0+ (1,0) [0|1] "" Vector__XXX
SG_ String0_Err_dsyChainRedun_CRC : 38|1@0+ (1,0) [0|1] "" Vector__XXX
SG_ String0_Err_dsyPrim_voltMeasOor : 39|1@0+ (1,0) [0|1] "" Vector__XXX
SG_ String0_Err_dsyRedun_voltMeasOor : 40|1@0+ (1,0) [0|1] "" Vector__XXX
SG_ String0_Err_dsyPrim_tempMeasOor : 41|1@0+ (1,0) [0|1] "" Vector__XXX
SG_ String0_Err_dsyRedun_tempMeasOor : 42|1@0+ (1,0) [0|1] "" Vector__XXX
SG_ String0_Err_CS_coulombCountMeas : 44|1@0+ (1,0) [0|1] "" Vector__XXX
SG_ String0_Err_CS_energyCountMeas : 45|1@0+ (1,0) [0|1] "" Vector__XXX
SG_ String0_Err_plaus_volt_spread : 55|1@0+ (1,0) [0|1] "" Vector__XXX
SG_ String0_Err_plaus_temp_spread : 54|1@0+ (1,0) [0|1] "" Vector__XXX
SG_ String0_fuseBlown : 6|1@0+ (1,0) [0|1] "" Vector__XXX
SG_ String0_Warning_overvoltage_MOL : 22|1@0+ (1,0) [0|1] "" Vector__XXX
SG_ String0_Warning_undervoltage_MOL : 23|1@0+ (1,0) [0|1] "" Vector__XXX
SG_ String0_Wrng_chargeOverTemp_MOL : 16|1@0+ (1,0) [0|1] "" Vector__XXX
SG_ String0_Wrng_dischrgOverTemp_MOL : 18|1@0+ (1,0) [0|1] "" Vector__XXX
SG_ String0_Wrng_chargeUnderTemp_MOL : 17|1@0+ (1,0) [0|1] "" Vector__XXX
SG_ String0_Wrng_dischrgUnderTmp_MOL : 19|1@0+ (1,0) [0|1] "" Vector__XXX
SG_ String0_Wrng_chargeOverCur_MOL : 20|1@0+ (1,0) [0|1] "" Vector__XXX
SG_ String0_Wrng_dischargOverCur_MOL : 21|1@0+ (1,0) [0|1] "" Vector__XXX
SG_ String0_Wrng_chargeOverTemp_RSL : 24|1@0+ (1,0) [0|1] "" Vector__XXX
SG_ String0_Wrng_chargeUnderTemp_RSL : 25|1@0+ (1,0) [0|1] "" Vector__XXX
SG_ String0_Wrng_dischrgOverTemp_RSL : 26|1@0+ (1,0) [0|1] "" Vector__XXX
SG_ String0_Wrng_dischrgUnderTmp_RSL : 27|1@0+ (1,0) [0|1] "" Vector__XXX
SG_ String0_Wrng_chargeOverCur_RSL : 28|1@0+ (1,0) [0|1] "" Vector__XXX
SG_ String0_Wrng_dischargOverCur_RSL : 29|1@0+ (1,0) [0|1] "" Vector__XXX
SG_ String0_Wrng_overvoltage_RSL : 30|1@0+ (1,0) [0|1] "" Vector__XXX
SG_ String0_Wrng_undervoltage_RSL : 31|1@0+ (1,0) [0|1] "" Vector__XXX
SG_ String0_Err_negativeContactor : 33|1@0+ (1,0) [0|1] "" Vector__XXX
SG_ String0_Err_CS_voltage1Meas : 46|1@0+ (1,0) [0|1] "" Vector__XXX
SG_ String0_Err_CS_voltage2Meas : 47|1@0+ (1,0) [0|1] "" Vector__XXX
SG_ String0_Err_CS_voltage3Meas : 48|1@0+ (1,0) [0|1] "" Vector__XXX

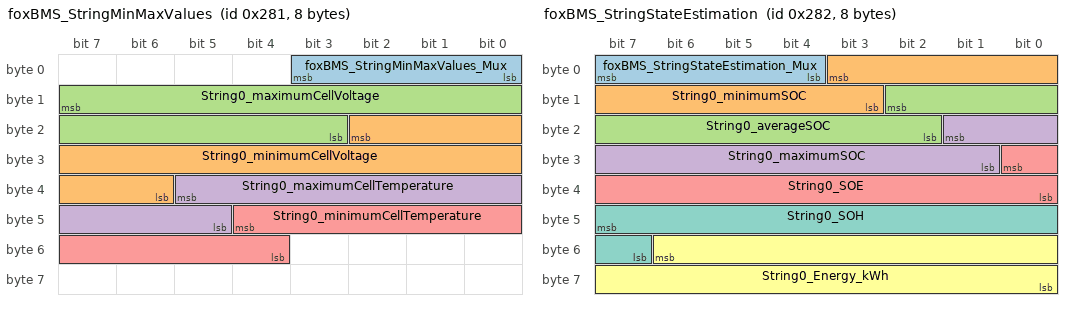
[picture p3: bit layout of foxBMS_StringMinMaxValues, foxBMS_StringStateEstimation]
BO_ 641 foxBMS_StringMinMaxValues: 8 Vector__XXX
SG_ foxBMS_StringMinMaxValues_Mux M : 3|4@0+ (1,0) [0|0] "" Vector__XXX
SG_ String0_minimumCellVoltage : 18|13@0+ (1,0) [0|8191] "mV" Vector__XXX
SG_ String0_maximumCellVoltage : 15|13@0+ (1,0) [0|8191] "mV" Vector__XXX
SG_ String0_maximumCellTemperature : 37|9@0- (0.5,0) [-128|127.5] "degC" Vector__XXX
SG_ String0_minimumCellTemperature : 44|9@0- (0.5,0) [-128|127.5] "degC" Vector__XXX

BO_ 642 foxBMS_StringStateEstimation: 8 Vector__XXX
SG_ foxBMS_StringStateEstimation_Mux M : 7|4@0+ (1,0) [0|0] "" Vector__XXX
SG_ String0_minimumSOC : 3|9@0+ (0.25,0) [0|127.75] "%" Vector__XXX
SG_ String0_averageSOC : 10|9@0+ (0.25,0) [0|127.5] "%" Vector__XXX
SG_ String0_maximumSOC : 17|9@0+ (0.25,0) [0|63.75] "%" Vector__XXX
SG_ String0_SOE : 24|9@0+ (0.25,0) [0|127.5] "%" Vector__XXX
SG_ String0_Energy_kWh : 54|15@0+ (0.01,0) [0|327.67] "kWh" Vector__XXX
SG_ String0_SOH : 47|9@0+ (0.25,0) [0|127.5] "%" Vector__XXX

BO_ 512 foxBMS_Debug: 8 Vector__XXX
SG_ foxBMS_Debug_Mux M : 7|8@0+ (1,0) [0|0] "" Vector__XXX
SG_ SetHundredthOfSeconds m1 : 15|7@0+ (1,0) [0|127] "" Vector__XXX
SG_ SetSeconds m1 : 8|6@0+ (1,0) [0|63] "" Vector__XXX
SG_ SetMinutes m1 : 18|6@0+ (1,0) [0|63] "" Vector__XXX
SG_ SetHours m1 : 28|5@0+ (1,0) [0|31] "" Vector__XXX
SG_ SetWeekday m1 : 39|3@0+ (1,0) [0|7] "" Vector__XXX
SG_ SetDay m1 : 36|5@0+ (1,0) [0|31] "" Vector__XXX
SG_ SetMonth m1 : 47|4@0+ (1,0) [0|15] "" Vector__XXX
SG_ SetYear m1 : 43|7@0+ (1,0) [0|127] "" Vector__XXX
SG_ foxBMS_GetMcuLotNumber m0 : 10|1@0+ (1,0) [0|1] "" Vector__XXX
SG_ foxBMS_GetBmsSoftwareVersion m0 : 8|1@0+ (1,0) [0|1] "" Vector__XXX
SG_ foxBMS_GetMcuUniqueDieId m0 : 9|1@0+ (1,0) [0|1] "" Vector__XXX
SG_ foxBMS_GetMcuWaferInformation m0 : 11|1@0+ (1,0) [0|1] "" Vector__XXX
SG_ foxBMS_GetCommitHash m0 : 12|1@1+ (1,0) [0|1] "" Vector__XXX
SG_ foxBMS_TriggerSoftwareReset m2 : 39|1@0+ (1,0) [0|1] "" Vector__XXX
SG_ InitializeFram m3 : 27|1@0+ (1,0) [0|1] "" Vector__XXX
SG_ foxBMS_RequestRtcTime m4 : 8|1@0+ (1,0) [0|1] "" Vector__XXX

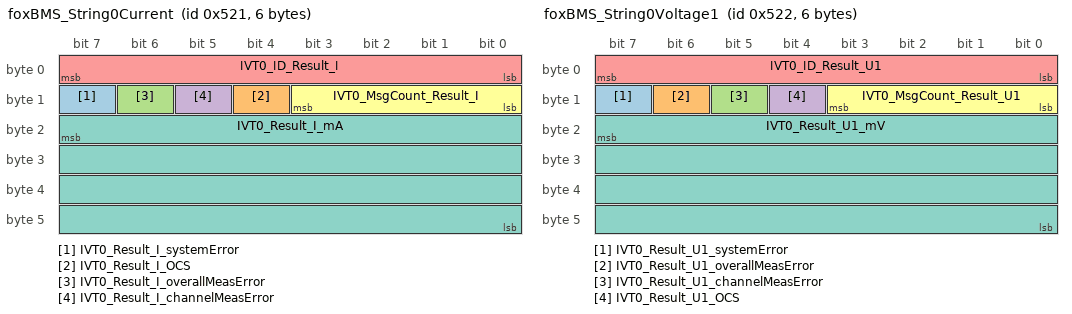
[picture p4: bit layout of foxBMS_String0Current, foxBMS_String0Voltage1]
BO_ 1313 foxBMS_String0Current: 6 Vector__XXX
SG_ IVT0_Result_I_systemError : 15|1@0+ (1,0) [0|1] "" Vector__XXX
SG_ IVT0_Result_I_OCS : 12|1@0+ (1,0) [0|1] "" Vector__XXX
SG_ IVT0_Result_I_overallMeasError : 14|1@0+ (1,0) [0|1] "" Vector__XXX
SG_ IVT0_Result_I_channelMeasError : 13|1@0+ (1,0) [0|1] "" Vector__XXX
SG_ IVT0_ID_Result_I : 7|8@0+ (1,0) [0|255] "" Vector__XXX
SG_ IVT0_MsgCount_Result_I : 11|4@0+ (1,0) [0|15] "" Vector__XXX
SG_ IVT0_Result_I_mA : 23|32@0- (1,0) [-2147483648|2147483647] "mA" Vector__XXX

BO_ 1314 foxBMS_String0Voltage1: 6 Vector__XXX
SG_ IVT0_Result_U1_systemError : 15|1@0+ (1,0) [0|1] "" Vector__XXX
SG_ IVT0_Result_U1_overallMeasError : 14|1@0+ (1,0) [0|1] "" Vector__XXX
SG_ IVT0_Result_U1_channelMeasError : 13|1@0+ (1,0) [0|1] "" Vector__XXX
SG_ IVT0_Result_U1_OCS : 12|1@0+ (1,0) [0|1] "" Vector__XXX
SG_ IVT0_ID_Result_U1 : 7|8@0+ (1,0) [1|1] "" Vector__XXX
SG_ IVT0_MsgCount_Result_U1 : 11|4@0+ (1,0) [0|15] "" Vector__XXX
SG_ IVT0_Result_U1_mV : 23|32@0- (1,0) [-2147483648|2147483647] "mV" Vector__XXX

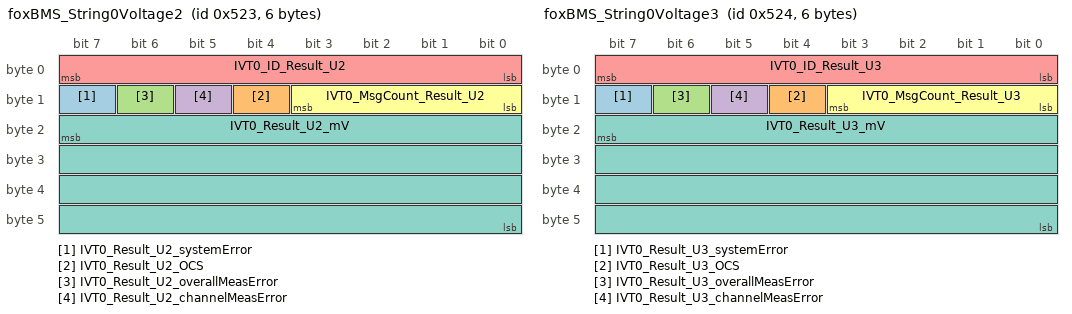
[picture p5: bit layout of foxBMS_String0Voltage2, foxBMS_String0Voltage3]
BO_ 1315 foxBMS_String0Voltage2: 6 Vector__XXX
SG_ IVT0_Result_U2_systemError : 15|1@0+ (1,0) [0|1] "" Vector__XXX
SG_ IVT0_Result_U2_OCS : 12|1@0+ (1,0) [0|1] "" Vector__XXX
SG_ IVT0_Result_U2_overallMeasError : 14|1@0+ (1,0) [0|1] "" Vector__XXX
SG_ IVT0_Result_U2_channelMeasError : 13|1@0+ (1,0) [0|1] "" Vector__XXX
SG_ IVT0_ID_Result_U2 : 7|8@0+ (1,0) [2|2] "" Vector__XXX
SG_ IVT0_MsgCount_Result_U2 : 11|4@0+ (1,0) [0|15] "" Vector__XXX
SG_ IVT0_Result_U2_mV : 23|32@0- (1,0) [-2147483648|2147483647] "mV" Vector__XXX

BO_ 1316 foxBMS_String0Voltage3: 6 Vector__XXX
SG_ IVT0_Result_U3_systemError : 15|1@0+ (1,0) [0|1] "" Vector__XXX
SG_ IVT0_Result_U3_OCS : 12|1@0+ (1,0) [0|1] "" Vector__XXX
SG_ IVT0_Result_U3_overallMeasError : 14|1@0+ (1,0) [0|1] "" Vector__XXX
SG_ IVT0_Result_U3_channelMeasError : 13|1@0+ (1,0) [0|1] "" Vector__XXX
SG_ IVT0_ID_Result_U3 : 7|8@0+ (1,0) [3|3] "" Vector__XXX
SG_ IVT0_MsgCount_Result_U3 : 11|4@0+ (1,0) [0|15] "" Vector__XXX
SG_ IVT0_Result_U3_mV : 23|32@0- (1,0) [-2147483648|2147483647] "mV" Vector__XXX

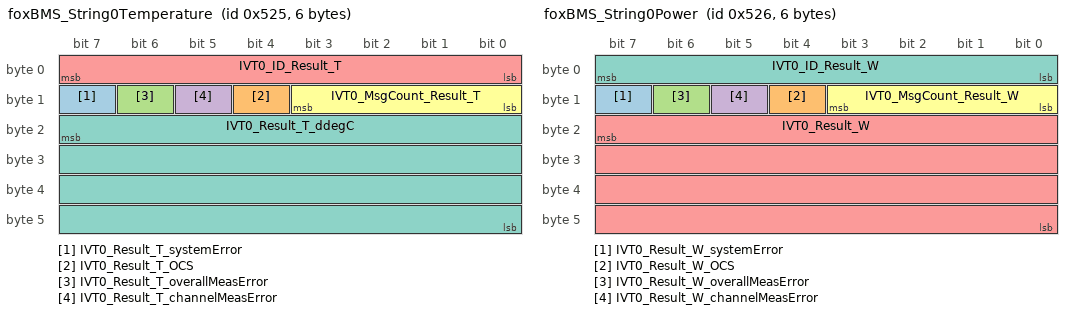
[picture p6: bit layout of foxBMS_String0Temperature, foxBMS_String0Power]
BO_ 1317 foxBMS_String0Temperature: 6 Vector__XXX
SG_ IVT0_Result_T_systemError : 15|1@0+ (1,0) [0|1] "" Vector__XXX
SG_ IVT0_Result_T_OCS : 12|1@0+ (1,0) [0|1] "" Vector__XXX
SG_ IVT0_Result_T_overallMeasError : 14|1@0+ (1,0) [0|1] "" Vector__XXX
SG_ IVT0_Result_T_channelMeasError : 13|1@0+ (1,0) [0|1] "" Vector__XXX
SG_ IVT0_ID_Result_T : 7|8@0+ (1,0) [4|4] "" Vector__XXX
SG_ IVT0_MsgCount_Result_T : 11|4@0+ (1,0) [0|15] "" Vector__XXX
SG_ IVT0_Result_T_ddegC : 23|32@0- (0.1,0) [-214748364.8|214748364.7] "ddegC" Vector__XXX

BO_ 1318 foxBMS_String0Power: 6 Vector__XXX
SG_ IVT0_Result_W_systemError : 15|1@0+ (1,0) [0|1] "" Vector__XXX
SG_ IVT0_Result_W_OCS : 12|1@0+ (1,0) [0|1] "" Vector__XXX
SG_ IVT0_Result_W_overallMeasError : 14|1@0+ (1,0) [0|1] "" Vector__XXX
SG_ IVT0_Result_W_channelMeasError : 13|1@0+ (1,0) [0|1] "" Vector__XXX
SG_ IVT0_Result_W : 23|32@0- (1,0) [-2147483648|2147483647] "W" Vector__XXX
SG_ IVT0_MsgCount_Result_W : 11|4@0+ (1,0) [0|15] "" Vector__XXX
SG_ IVT0_ID_Result_W : 7|8@0+ (1,0) [5|5] "" Vector__XXX

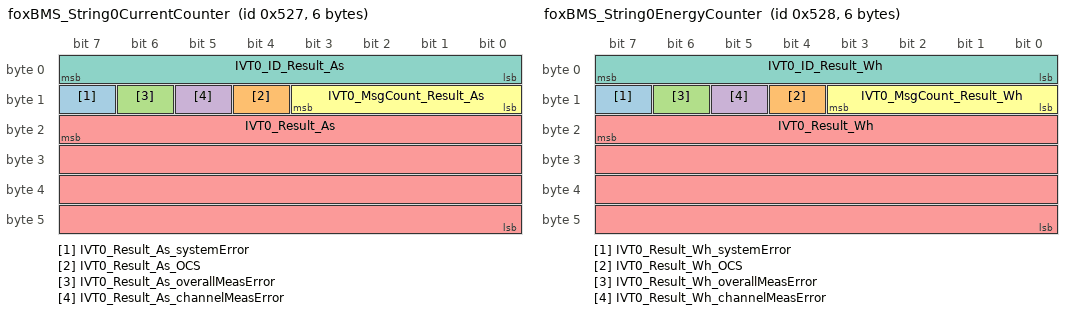
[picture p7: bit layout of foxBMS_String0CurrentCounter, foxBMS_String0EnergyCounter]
BO_ 1319 foxBMS_String0CurrentCounter: 6 Vector__XXX
SG_ IVT0_Result_As_systemError : 15|1@0+ (1,0) [0|1] "" Vector__XXX
SG_ IVT0_Result_As_OCS : 12|1@0+ (1,0) [0|1] "" Vector__XXX
SG_ IVT0_Result_As_overallMeasError : 14|1@0+ (1,0) [0|1] "" Vector__XXX
SG_ IVT0_Result_As_channelMeasError : 13|1@0+ (1,0) [0|1] "" Vector__XXX
SG_ IVT0_Result_As : 23|32@0- (1,0) [-2147483648|2147483647] "As" Vector__XXX
SG_ IVT0_MsgCount_Result_As : 11|4@0+ (1,0) [0|15] "" Vector__XXX
SG_ IVT0_ID_Result_As : 7|8@0+ (1,0) [6|6] "" Vector__XXX

BO_ 1320 foxBMS_String0EnergyCounter: 6 Vector__XXX
SG_ IVT0_Result_Wh_systemError : 15|1@0+ (1,0) [0|1] "" Vector__XXX
SG_ IVT0_Result_Wh_OCS : 12|1@0+ (1,0) [0|1] "" Vector__XXX
SG_ IVT0_Result_Wh_overallMeasError : 14|1@0+ (1,0) [0|1] "" Vector__XXX
SG_ IVT0_Result_Wh_channelMeasError : 13|1@0+ (1,0) [0|1] "" Vector__XXX
SG_ IVT0_Result_Wh : 23|32@0- (1,0) [-2147483648|2147483647] "Wh" Vector__XXX
SG_ IVT0_MsgCount_Result_Wh : 11|4@0+ (1,0) [0|15] "" Vector__XXX
SG_ IVT0_ID_Result_Wh : 7|8@0+ (1,0) [7|7] "" Vector__XXX

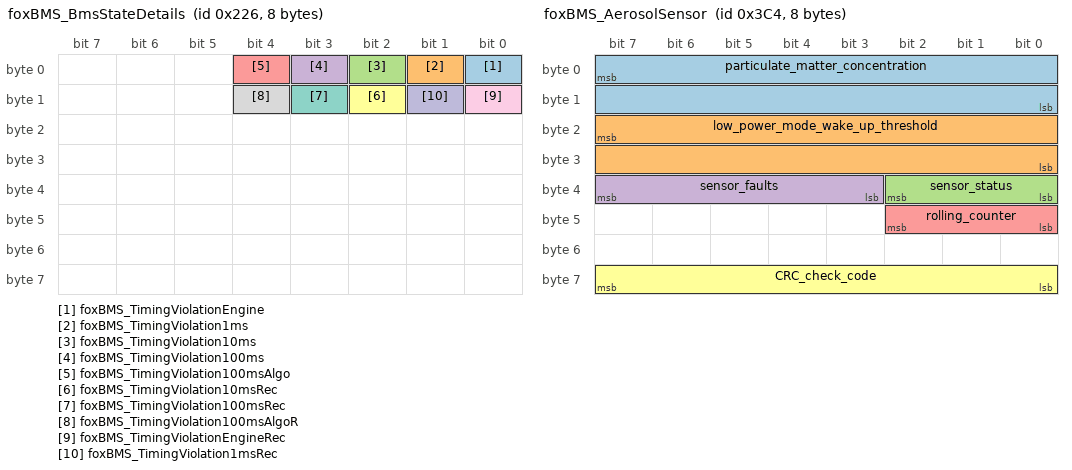
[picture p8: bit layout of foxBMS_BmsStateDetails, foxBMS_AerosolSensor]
BO_ 550 foxBMS_BmsStateDetails: 8 Vector__XXX
SG_ foxBMS_TimingViolationEngine : 0|1@0+ (1,0) [0|1] "" Vector__XXX
SG_ foxBMS_TimingViolation1ms : 1|1@0+ (1,0) [0|1] "" Vector__XXX
SG_ foxBMS_TimingViolation10ms : 2|1@0+ (1,0) [0|1] "" Vector__XXX
SG_ foxBMS_TimingViolation100ms : 3|1@0+ (1,0) [0|1] "" Vector__XXX
SG_ foxBMS_TimingViolation100msAlgo : 4|1@0+ (1,0) [0|1] "" Vector__XXX
SG_ foxBMS_TimingViolation10msRec : 10|1@0+ (1,0) [0|1] "" Vector__XXX
SG_ foxBMS_TimingViolation100msRec : 11|1@0+ (1,0) [0|1] "" Vector__XXX
SG_ foxBMS_TimingViolation100msAlgoR : 12|1@0+ (1,0) [0|1] "" Vector__XXX
SG_ foxBMS_TimingViolationEngineRec : 8|1@0+ (1,0) [0|1] "" Vector__XXX
SG_ foxBMS_TimingViolation1msRec : 9|1@0+ (1,0) [0|1] "" Vector__XXX

BO_ 551 foxBMS_DebugResponse: 8 Vector__XXX
SG_ foxBMS_DebugResponse_Mux M : 7|8@0+ (1,0) [0|0] "" Vector__XXX
SG_ MCU_waferNumber m3 : 15|8@0+ (1,0) [0|1] "" Vector__XXX
SG_ MCU_xWaferCoordinate m3 : 27|12@0+ (1,0) [0|1] "" Vector__XXX
SG_ MCU_yWaferCoordinate m3 : 23|12@0+ (1,0) [0|1] "" Vector__XXX
SG_ MCU_LotNumber m2 : 15|32@0+ (1,0) [0|1] "" Vector__XXX
SG_ MCU_uniqueId m1 : 15|32@0+ (1,0) [0|4294967295] "" Vector__XXX
SG_ foxBMS_dirtyFlag m0 : 33|1@0+ (1,0) [0|1] "" Vector__XXX
SG_ foxBMS_majorVersionNumber m0 : 15|8@0+ (1,0) [0|255] "" Vector__XXX
SG_ foxBMS_minorVersionNumber m0 : 23|8@0+ (1,0) [0|255] "" Vector__XXX
SG_ foxBMS_patchVersionNumber m0 : 31|8@0+ (1,0) [0|255] "" Vector__XXX
SG_ foxBMS_releaseDistance m0 : 39|5@0+ (1,0) [0|31] "" Vector__XXX
SG_ foxBMS_releaseDistanceOverflow m0 : 34|1@0+ (1,0) [0|1] "" Vector__XXX
SG_ foxBMS_underVersionControl m0 : 32|1@0+ (1,0) [0|1] "" Vector__XXX
SG_ foxBMS_MagicBootData m15 : 15|56@0+ (1,0) [0|1] "" Vector__XXX
SG_ GetDay m4 : 36|5@0+ (1,0) [0|31] "" Vector__XXX
SG_ GetHours m4 : 28|5@0+ (1,0) [0|31] "" Vector__XXX
SG_ GetHundredthOfSeconds m4 : 15|7@0+ (1,0) [0|127] "" Vector__XXX
SG_ GetMinutes m4 : 18|6@0+ (1,0) [0|63] "" Vector__XXX
SG_ GetMonth m4 : 47|4@0+ (1,0) [0|15] "" Vector__XXX
SG_ GetSeconds m4 : 8|6@0+ (1,0) [0|63] "" Vector__XXX
SG_ GetWeekday m4 : 39|3@0+ (1,0) [0|7] "" Vector__XXX
SG_ GetYear m4 : 43|7@0+ (1,0) [0|127] "" Vector__XXX
SG_ shortHash m5 : 15|56@0+ (1,0) [0|0] "" Vector__XXX

BO_ 513 foxBMS_UnsupportedMultiplexerVal: 8 Vector__XXX
SG_ foxBMS_MessageId : 7|32@0+ (1,0) [0|1] "" Vector__XXX
SG_ foxBMS_MultiplexerValue : 39|32@0+ (1,0) [0|1] "" Vector__XXX

BO_ 255 foxBMS_FatalErrors: 8 Vector__XXX
SG_ foxBMS_FatalErrors_Mux M : 7|8@0+ (1,0) [0|0] "" Vector__XXX

BO_ 964 foxBMS_AerosolSensor: 8 Vector__XXX
SG_ particulate_matter_concentration : 7|16@0+ (1,0) [0|65535] "" Vector__XXX
SG_ low_power_mode_wake_up_threshold : 23|16@0+ (1,0) [0|65535] "" Vector__XXX
SG_ sensor_status : 34|3@0+ (1,0) [0|7] "" Vector__XXX
SG_ sensor_faults : 39|5@0+ (1,0) [0|31] "" Vector__XXX
SG_ rolling_counter : 42|3@0+ (1,0) [0|7] "" Vector__XXX
SG_ CRC_check_code : 63|8@0+ (1,0) [0|255] "" Vector__XXX

CM_ BO_ 546 "(in:can_cbs_tx_pack-values-p0.c:CANTX_PackValues, fv:tx)";
CM_ SG_ 546 foxBMS_packCurrent "Battery pack current";
CM_ SG_ 546 foxBMS_batteryVoltage "Battery voltage between negative and positive pole of the battery";
CM_ SG_ 546 foxBMS_busVoltage "Battery voltage between negative pole and after main positive contactor";
CM_ SG_ 546 foxBMS_packPower "Battery power";
CM_ BO_ 548 "(in:can_cbs_tx_pack-limits.c:CANTX_LimitValues, fv:tx)";
CM_ SG_ 548 foxBMS_maxChargeCurrent "Maximum battery pack charge current";
CM_ SG_ 548 foxBMS_maxDischargeCurrent "Maximum battery pack discharge current";
CM_ BO_ 547 "(in:can_cbs_tx_pack-minimum-maximum-values.c:CANTX_MinimumMaximumValues, fv:tx)";
CM_ SG_ 547 foxBMS_minimumCellVoltage "Minimum cell voltage of all connected strings, if no string connected maximum value of whole system is transmitted";
CM_ SG_ 547 foxBMS_maximumCellVoltage "Maximum cell voltage of all connected strings, if no string connected maximum value of whole system is transmitted";
CM_ SG_ 547 foxBMS_maximumCellTemp "Maximum cell temperature of all connected strings, if no string connected maximum value of whole system is transmitted";
CM_ SG_ 547 foxBMS_minimumCellTemp "Minium cell temperature of all connected string, if no string connected maximum value of whole system is transmitted";
CM_ BO_ 640 "Message contains string voltage, current and power (in:can_cbs_tx_pack-values-p0.c:CANTX_StringValuesP0, fv:tx)";
CM_ BO_ 643 "Message contains energy counting value (in:can_cbs_tx_pack-values-p0.c:CANTX_StringValuesP1, fv:tx)";
CM_ SG_ 643 foxBMS_String0EnergyCount "Current sensor string 0 energy counting value";
CM_ BO_ 549 "(in:can_cbs_tx_pack-state-estimation.c:CANTX_PackStateEstimation, fv:tx)";
CM_ SG_ 549 foxBMS_packSoc "SOC currently connected to HV bus (100% if all strings connected and all strings at 100%)";
CM_ SG_ 549 foxBMS_packSoe "SOE currently connected to HV bus (100% if all strings connected and all strings at 100%)";
CM_ SG_ 549 foxBMS_packEnergy "Energy left in Wh that is currently connected to HV bus";
CM_ BO_ 576 "(in:can_cbs_tx_cell-voltages.c:CANTX_CellVoltages, fv:tx)";
CM_ BO_ 592 "(in:can_cbs_tx_cell-temperatures.c:CANTX_CellTemperatures, fv:tx)";
CM_ BO_ 560 "(in:can_cbs_rx_bms-state-request.c:CANRX_BmsStateRequest, fv:rx)";
CM_ SG_ 560 foxBMS_modeRequest "0x0: Disconnect strings from HV bus, 0x01: Connect strings to HV bus to start discharge, 0x02: Connect strings to HV bus to start charging";
CM_ SG_ 560 foxBMS_activateBalancing "0: Deactivate balancing, 1: Activate balancing";
CM_ SG_ 560 foxBMS_balancingThreshold "Required voltage difference to minimum cell voltage to activate balancing";
CM_ SG_ 560 foxBMS_externallyPrecharged "0x0: HV bus not externally precharged, 0x01: HV bus externally precharged";
CM_ SG_ 560 foxBMS_resetFlags "0x01: reset persistent flags";
CM_ SG_ 560 foxBMS_chargerConnected "0x00: charger not connected, 0x01: charger connected";
CM_ SG_ 560 foxBMS_disableInsulationMon "0x00: Check battery system insulation, 0x01: Do not check insulation of battery system";
CM_ SG_ 560 foxBMS_heaterOverride_ON "0: no override active, 1: override active -> force heater on";
CM_ SG_ 560 foxBMS_heaterOverride_OFF "0: no override active, 1: override active -> force heater off";
CM_ BO_ 544 "Message contains foxBMS state (in:can_cbs_tx_bms-state.c:CANTX_BmsState, fv:tx)";
CM_ SG_ 544 foxBMS_generalError "0x00: No error detected, 0x01: Error detected";
CM_ SG_ 544 foxBMS_generalWarning "0x00: No warning detected, 0x01: Warning detected";
CM_ SG_ 544 foxBMS_Error_dieTemperatureMCU "0x00: No error, 0x01: Error detected";
CM_ SG_ 544 foxBMS_Error_OvertempPCB "foxBMS Master-PCB: 0x00: No error, 0x01: Error detected";
CM_ SG_ 544 foxBMS_Error_UndertempPCB "foxBMS Master-PCB: 0x00: No error, 0x01: Error detected";
CM_ SG_ 544 foxBMS_Error_PrechargeVolt "0x00: precharging successful, 0x01: precharge aborted because of voltage difference";
CM_ SG_ 544 foxBMS_Error_PrechargeCurrent "0x00: precharging successful, 0x01: precharge aborted because current limit violated";
CM_ SG_ 544 foxBMS_heaterState "0x00: Heater not activated, 0x01: Heater activated";
CM_ SG_ 544 foxBMS_coolingState "0x00: Cooling not activated, 0x01: Cooling activated";
CM_ SG_ 544 foxBMS_insulationMonitoring "0x00: insulation monitoring active, 0x01: insulation monitoring not active";
CM_ SG_ 544 foxBMS_chargingComplete "0x01: charging complete";
CM_ SG_ 544 foxBMS_EmergencyShutoff "The BMS is preparing to open the contactors soon due to detected error";
CM_ SG_ 544 foxBMS_MainFuseBlown "0x00: fuse okay, 0x01: fuse blown";
CM_ SG_ 544 foxBMS_Error_Interlock "0x00: interlock okay, 0x01: interlock open";
CM_ SG_ 544 foxBMS_Error_Insulation "0x00: No error, 0x01: Error detected";
CM_ SG_ 544 foxBMS_Error_Cantiming "0x00: No error, 0x01: Error detected";
CM_ SG_ 544 foxBMS_Error_PackOvercurr_Charge "0x00: No error, 0x01: Error detected";
CM_ SG_ 544 foxBMS_Error_PackOvercur_Dischrg "0x00: No error, 0x01: Error detected";
CM_ SG_ 544 foxBMS_SysMonError "If this bit is set, it indicates that a task has violated its timing requirements.";
CM_ SG_ 544 foxBMS_alertFlag "foxBMS Alter flag: 0x00: No error, 0x01: Alert flag set";
CM_ SG_ 544 foxBMS_NvramCrcError "0x00: No NVRAM CRC Error detected, 0x01: NVRAM CRC Error detected";
CM_ BO_ 545 "Message contains string related error and warning flags (in:can_cbs_tx_bms-state.c:CANTX_StringState, fv:tx)";
CM_ SG_ 545 String0_stringConnected "0x00: String not connected, 0x01: String connected to HV bus";
CM_ SG_ 545 String0_balancing_active "0x00: No balancing active, 0x01: Balancing in this string active";
CM_ SG_ 545 String0_Err_overtemp_charge "0x00: No error, 0x01: Error: Flag will be set if maximum cell temperature is above 45 degree Celsius.";
CM_ SG_ 545 String0_Err_undertemp_charge "0x00: No error, 0x01: Error: Flag will be set if minimum cell temperature is below 0 degree Celsius.";
CM_ SG_ 545 String0_Err_overtemp_discharge "0x00: No error, 0x01: Error: Flag will be set if maximum cell temperature is above 60 degree Celsius.";
CM_ SG_ 545 String0_Err_undertemp_discharge "0x00: No error, 0x01: Error: Flag will be set if minimum cell temperature is below -20 degree Celsius.";
CM_ SG_ 545 String0_Err_Overcurrent_charge "0x00: No error, 0x01: Error: Flag will be set if string charge current is above 30400mA.";
CM_ SG_ 545 String0_Err_Overcurre_discharge "0x00: No error, 0x01: Error: Flag will be set if discharge current is above maximum string current.";
CM_ SG_ 545 String0_Err_Overvoltage "0x00: No error, 0x01: Error: Flag will be set if maximum cell voltage is above 4200mV.";
CM_ SG_ 545 String0_Err_Undervoltage "0x00: No error, 0x01: Error: Flag will be set if minimum cell voltage is below 3000mV. This equals roughly 4% remaining SOC. Minimum data sheet values if 2500mV.";
CM_ SG_ 545 String0_Err_deep_discharge "0x00: No error, 0x01: Error";
CM_ SG_ 545 String0_Err_CS_currentMeas "0x00: No error, 0x01: Error";
CM_ SG_ 545 String0_Err_positiveContactor "0x00: No error, 0x01: Error";
CM_ SG_ 545 String0_Err_openWire "0x00: No error, 0x01: Error";
CM_ SG_ 545 String0_openWireNumber "Number of first open wire that has been detected in this string";
CM_ SG_ 545 String0_Err_plaus_cell_volt "0x00: No error, 0x01: Error";
CM_ SG_ 545 String0_Err_plaus_cell_temp "0x00: No error, 0x01: Error";
CM_ SG_ 545 String0_Err_plaus_string_volt "0x00: No error, 0x01: Error";
CM_ SG_ 545 String0_Err_slave_hardware "0x00: No error, 0x01: Error";
CM_ SG_ 545 String0_Err_dsyChainBase_Comm "0x00: No error, 0x01: Error (i.e. SPI)";
CM_ SG_ 545 String0_Err_dsyChainPrim_CRC "0x00: No error, 0x01: Error";
CM_ SG_ 545 String0_Err_dsyChainRedun_Comm "0x00: No error, 0x01: Error";
CM_ SG_ 545 String0_Err_dsyChainRedun_CRC "0x00: No error, 0x01: Error";
CM_ SG_ 545 String0_Err_dsyPrim_voltMeasOor "0x00: No error, 0x01: Error";
CM_ SG_ 545 String0_Err_dsyRedun_voltMeasOor "0x00: No error, 0x01: Error";
CM_ SG_ 545 String0_Err_dsyPrim_tempMeasOor "0x00: No error, 0x01: Error";
CM_ SG_ 545 String0_Err_dsyRedun_tempMeasOor "0x00: No error, 0x01: Error";
CM_ SG_ 545 String0_Err_CS_coulombCountMeas "0x00: No error, 0x01: Error";
CM_ SG_ 545 String0_Err_CS_energyCountMeas "0x00: No error, 0x01: Error";
CM_ SG_ 545 String0_Err_plaus_volt_spread "0x00: No error, 0x01: Error";
CM_ SG_ 545 String0_Err_plaus_temp_spread "0x00: No error, 0x01: Error";
CM_ SG_ 545 String0_Err_negativeContactor "0x00: No error, 0x01: Error";
CM_ BO_ 641 "Message contains minimum and maximum cell temperature and cell voltage values of respective string (in:can_cbs_tx_pack-minimum-maximum-values.c:CANTX_StringMinimumMaximumValues, fv:tx)";
CM_ SG_ 641 String0_minimumCellVoltage "Minimum cell voltage in this string";
CM_ SG_ 641 String0_maximumCellVoltage "Maximum cell voltage in this string";
CM_ SG_ 641 String0_maximumCellTemperature "Maximum cell temperature in this string";
CM_ SG_ 641 String0_minimumCellTemperature "Minium cell temperature in this string";
CM_ BO_ 642 "Message contains SOC, SOE and SOH state estimations (in:can_cbs_tx_string-state-estimation.c:CANTX_StringStateEstimation, fv:tx)";
CM_ SG_ 642 String0_SOE "SOE is depending on current direction, if battery system is charging: SOE_max is transmitted, else SOE_min";
CM_ SG_ 642 String0_Energy_kWh "Remaining energy left in this string";
CM_ BO_ 512 "Reserved - for debug/development purpose only (in:can_cbs_rx_debug.c:CANRX_Debug, fv:rx)";
CM_ BO_ 1313 "Current sensor string 0: current (in:can_cbs_rx_current-sensor.c:CANRX_CurrentSensor, fv:rx); Isabellenhuette data sheet name: IVT0_Msg_Result_I";
CM_ BO_ 1314 "Current sensor string 0: voltage 1 (in:can_cbs_rx_current-sensor.c:CANRX_CurrentSensor, fv:rx); Isabellenhuette data sheet name: IVT0_Msg_Result_U1";
CM_ BO_ 1315 "Current sensor string 0: voltage 2 (in:can_cbs_rx_current-sensor.c:CANRX_CurrentSensor, fv:rx); Isabellenhuette data sheet name: IVT0_Msg_Result_U2";
CM_ BO_ 1316 "Current sensor string 0: voltage 3 (in:can_cbs_rx_current-sensor.c:CANRX_CurrentSensor, fv:rx); Isabellenhuette data sheet name: IVT0_Msg_Result_U3";
CM_ BO_ 1317 "Current sensor string 0: temperature (in:can_cbs_rx_current-sensor.c:CANRX_CurrentSensor, fv:rx); Isabellenhuette data sheet name: IVT0_Msg_Result_T";
CM_ BO_ 1318 "Current sensor string 0: power (in:can_cbs_rx_current-sensor.c:CANRX_CurrentSensor, fv:rx); Isabellenhuette data sheet name: IVT0_Msg_Result_W";
CM_ BO_ 1319 "Current sensor string 0: coulomb counting (in:can_cbs_rx_current-sensor.c:CANRX_CurrentSensor, fv:rx); Isabellenhuette data sheet name: IVT0_Msg_Result_As";
CM_ BO_ 1320 "Current sensor string 0: energy counting (in:can_cbs_rx_current-sensor.c:CANRX_CurrentSensor, fv:rx); Isabellenhuette data sheet name: IVT0_Msg_Result_Wh";
CM_ BO_ 550 "Transmits details on flags transmitted by foxBMS_State (in:can_cbs_tx_bms-state.c:CANTX_BmsStateDetails, fv:tx)";
CM_ SG_ 550 foxBMS_TimingViolationEngine "Indicates whether the timing of the engine task has been violated.";
CM_ SG_ 550 foxBMS_TimingViolation1ms "Indicates whether the timing of the 1ms task has been violated.";
CM_ SG_ 550 foxBMS_TimingViolation10ms "Indicates whether the timing of the 10ms task has been violated.";
CM_ SG_ 550 foxBMS_TimingViolation100ms "Indicates whether the timing of the 100ms task has been violated.";
CM_ SG_ 550 foxBMS_TimingViolation100msAlgo "Indicates whether the timing of the 100ms algorithm task has been violated.";
CM_ SG_ 550 foxBMS_TimingViolation10msRec "Indicates whether a violation of the timing of the 10ms task has been recorded.";
CM_ SG_ 550 foxBMS_TimingViolation100msRec "Indicates whether a violation of the timing of the 100ms task has been recorded.";
CM_ SG_ 550 foxBMS_TimingViolation100msAlgoR "Indicates whether a violation of the timing of the 100ms algorithm task has been recorded.";
CM_ SG_ 550 foxBMS_TimingViolationEngineRec "Indicates whether a violation of the timing of the engine task has been recorded.";
CM_ SG_ 550 foxBMS_TimingViolation1msRec "Indicates whether a violation of the timing of the 1ms task has been recorded.";
CM_ BO_ 551 "(in:can_cbs_tx_debug-response.c:CANTX_DebugResponse, fv:tx)";
CM_ SG_ 551 MCU_waferNumber "wafer number of the MCU (read from DIEDL register)";
CM_ SG_ 551 MCU_xWaferCoordinate "x coordinate of the MCU die on the wafer (read from DIEIDL register)";
CM_ SG_ 551 MCU_yWaferCoordinate "y coordinate of the MCU die on the wafer (read from DIEIDL register)";
CM_ SG_ 551 MCU_LotNumber "lot number of the MCU (read from DIEIDH register)";
CM_ SG_ 551 MCU_uniqueId "Content of Device Identification Register (DEVID)";
CM_ BO_ 513 "(in:can_cbs_tx_debug-unsupported-multiplexer-values.c:CANTX_UnsupportedMultiplexerValue, fv:tx)";
CM_ BO_ 255 "(in:can_cbs_tx_crash-dump.c:CANTX_SendReasonsForFatalErrors, fv:tx)";
CM_ BO_ 964 "(in:can_cbs_rx_aerosol-sensor.c:CANRX_AerosolSensor, fv:rx)";

BA_DEF_  "BusType" STRING ;
BA_DEF_ BO_  "GenMsgCycleTime" INT 0 65535;
BA_DEF_ SG_  "GenSigStartValue" FLOAT -3.4E+038 3.4E+038;
BA_DEF_ SG_  "SigType" ENUM "Default","Range","RangeSigned","ASCII","Discrete","Control","ReferencePGN","DTC","StringDelimiter","StringLength","StringLengthControl","MessageCounter","MessageChecksum";

BA_DEF_DEF_  "BusType" "CAN";
BA_DEF_DEF_  "GenMsgCycleTime" 0;
BA_DEF_DEF_  "GenSigStartValue" 0;
BA_DEF_DEF_  "SigType" "Default";

BA_ "GenMsgCycleTime" BO_ 546 100;
BA_ "GenMsgCycleTime" BO_ 548 100;
BA_ "GenMsgCycleTime" BO_ 547 100;
BA_ "GenMsgCycleTime" BO_ 640 100;
BA_ "GenMsgCycleTime" BO_ 643 100;
BA_ "GenMsgCycleTime" BO_ 549 1000;
BA_ "GenMsgCycleTime" BO_ 576 5400;
BA_ "GenMsgCycleTime" BO_ 592 4500;
BA_ "GenMsgCycleTime" BO_ 544 100;
BA_ "GenMsgCycleTime" BO_ 545 100;
BA_ "GenMsgCycleTime" BO_ 641 100;
BA_ "GenMsgCycleTime" BO_ 642 1000;
BA_ "GenMsgCycleTime" BO_ 550 1000;
BA_ "GenMsgCycleTime" BO_ 964 1000;

BA_ "GenSigStartValue" SG_ 1314 IVT0_ID_Result_U1 1;
BA_ "GenSigStartValue" SG_ 1315 IVT0_ID_Result_U2 2;
BA_ "GenSigStartValue" SG_ 1316 IVT0_ID_Result_U3 3;
BA_ "GenSigStartValue" SG_ 1317 IVT0_ID_Result_T 4;
BA_ "GenSigStartValue" SG_ 1318 IVT0_ID_Result_W 5;
BA_ "GenSigStartValue" SG_ 1319 IVT0_ID_Result_As 6;
BA_ "GenSigStartValue" SG_ 1320 IVT0_ID_Result_Wh 7;

BA_ "SigType" SG_ 551 shortHash 3;

VAL_ 640 foxBMS_StringValuesP0_Mux 0 "mux_valuesP0String_0" ;
VAL_ 643 foxBMS_StringValuesP1_Mux 0 "mux_valuesP1String_0" ;
VAL_ 576 foxBMS_CellVoltages_Mux 0 "mux_cellVoltage_000_003" 1 "mux_cellVoltage_004_007" 2 "mux_cellVoltage_008_011" 3 "mux_cellVoltage_012_015" 4 "mux_cellVoltage_016_019" 5 "mux_cellVoltage_020_023" 6 "mux_cellVoltage_024_027" 7 "mux_cellVoltage_028_031" 8 "mux_cellVoltage_032_035" 9 "mux_cellVoltage_036_039" 10 "mux_cellVoltage_040_043" 11 "mux_cellVoltage_044_047" 12 "mux_cellVoltage_048_051" 13 "mux_cellVoltage_052_055" 14 "mux_cellVoltage_056_059" 15 "mux_cellVoltage_060_063" 16 "mux_cellVoltage_064_067" 17 "mux_cellVoltage_068_071" 18 "mux_cellVoltage_072_075" 19 "mux_cellVoltage_076_079" 20 "mux_cellVoltage_080_083" 21 "mux_cellVoltage_084_087" 22 "mux_cellVoltage_088_091" 23 "mux_cellVoltage_092_095" 24 "mux_cellVoltage_096_099" 25 "mux_cellVoltage_100_103" 26 "mux_cellVoltage_104_107" 27 "mux_cellVoltage_108_111" 28 "mux_cellVoltage_112_115" 29 "mux_cellVoltage_116_119" 30 "mux_cellVoltage_120_123" 31 "mux_cellVoltage_124_127" 32 "mux_cellVoltage_128_131" 33 "mux_cellVoltage_132_135" 34 "mux_cellVoltage_136_139" 35 "mux_cellVoltage_140_143"
36 "mux_cellVoltage_144_147" 37 "mux_cellVoltage_148_151" 38 "mux_cellVoltage_152_155" 39 "mux_cellVoltage_156_159" 40 "mux_cellVoltage_160_163" 41 "mux_cellVoltage_164_167" 42 "mux_cellVoltage_168_171" 43 "mux_cellVoltage_172_175" 44 "mux_cellVoltage_176_179" 45 "mux_cellVoltage_180_183" 46 "mux_cellVoltage_184_187" 47 "mux_cellVoltage_188_191" 48 "mux_cellVoltage_192_195" 49 "mux_cellVoltage_196_199" 50 "mux_cellVoltage_200_203" 51 "mux_cellVoltage_204_207" 52 "mux_cellVoltage_208_211" 53 "mux_cellVoltage_212_215" ;
VAL_ 592 foxBMS_CellTemperatures_Mux 0 "mux_cellTemperature_000_005" 1 "mux_cellTemperature_006_011" 2 "mux_cellTemperature_012_017" 3 "mux_cellTemperature_018_023" 4 "mux_cellTemperature_024_029" 5 "mux_cellTemperature_030_035" 6 "mux_cellTemperature_036_041" 7 "mux_cellTemperature_042_047" 8 "mux_cellTemperature_048_053" 9 "mux_cellTemperature_054_059" 10 "mux_cellTemperature_060_065" 11 "mux_cellTemperature_066_071" 12 "mux_cellTemperature_072_077" 13 "mux_cellTemperature_078_083" 14 "mux_cellTemperature_084_089" 15 "mux_cellTemperature_090_095" 16 "mux_cellTemperature_096_101" 17 "mux_cellTemperature_102_107" 18 "mux_cellTemperature_108_113" 19 "mux_cellTemperature_114_119" 20 "mux_cellTemperature_120_125" 21 "mux_cellTemperature_126_131" 22 "mux_cellTemperature_132_137" 23 "mux_cellTemperature_138_143" 24 "mux_cellTemperature_144_149" 25 "mux_cellTemperature_150_155" 26 "mux_cellTemperature_156_161" 27 "mux_cellTemperature_162_167" 28 "mux_cellTemperature_168_173" 29 "mux_cellTemperature_174_179" ;
VAL_ 545 foxBMS_StringState_Mux 0 "mux_stateString0" ;
VAL_ 641 foxBMS_StringMinMaxValues_Mux 0 "mux_minMaxValuesString0" ;
VAL_ 642 foxBMS_StringStateEstimation_Mux 0 "mux_String0_SOC_SOE" ;
VAL_ 512 foxBMS_Debug_Mux 1 "foxBMS_Rtc" 0 "foxBMS_VersionInfo" 2 "foxBMS_SoftwareReset" 3 "foxBMS_FramInitialization" 4 "foxBMS_TimeInfo" ;
VAL_ 551 foxBMS_DebugResponse_Mux 3 "foxBMS_McuWaferInformation" 2 "foxBMS_McuLotNumber" 1 "foxBMS_McuUniqueDieId" 0 "foxBMS_BmsSoftwareVersionInfo" 15 "foxBMS_BootInformation" 4 "foxBMS_RtcTime" 5 "foxBMS_CommitHash" ;
VAL_ 255 foxBMS_FatalErrors_Mux 0 "StackOverflow" ;
VAL_ 560 foxBMS_modeRequest 0 "Standby" 1 "Discharge" 2 "Charge" ;
VAL_ 544 foxBMS_State 0 "BMS_UNINITIALIZED" 1 "BMS_INITIALIZATION" 2 "BMS_INITIALIZED" 3 "BMS_IDLE" 4 "BMS_OPEN_CONTACTORS" 5 "BMS_STANDBY" 6 "BMS_PRECHARGE" 7 "BMS_NORMAL" 8 "BMS_DISCHARGE" 9 "BMS_CHARGE" 10 "BMS_ERROR" 11 "BMS_UNDEFINED" ;
VAL_ 544 foxBMS_Error_dieTemperatureMCU 0 "No Error" 1 "Error" ;
VAL_ 544 foxBMS_Error_Interlock 0 "No Error" 1 "Error" ;
VAL_ 544 foxBMS_alertFlag 0 "No Error" 1 "Error" ;
VAL_ 544 foxBMS_NvramCrcError 0 "No Error" 1 "Error" ;
VAL_ 545 String0_Err_deep_discharge 0 "No Error" 1 "Error" ;
VAL_ 545 String0_Err_positiveContactor 0 "No Error" 1 "Error" ;
VAL_ 545 String0_fuseBlown 0 "Fuse okay" 1 "Fuse blown" ;
VAL_ 545 String0_Err_negativeContactor 0 "No Error" 1 "Error" ;
VAL_ 512 SetWeekday 1 "Monday" 2 "Tuesday" 3 "Wednesday" 4 "Thursday" 5 "Friday" 6 "Saturday" 0 "Sunday" ;
VAL_ 512 SetMonth 1 "January" 2 "February" 3 "March" 4 "April" 5 "May" 6 "June" 7 "July" 8 "August" 9 "September" 10 "October" 11 "November" 12 "December" ;
VAL_ 512 foxBMS_TriggerSoftwareReset 0 "NO_SOFTWARE_RESET" 1 "SOFTWARE_RESET" ;
VAL_ 512 InitializeFram 0 "NO_FRAM_INITIALIZATION" 1 "FRAM_INITIALIZATION" ;
VAL_ 551 GetMonth 1 "January" 2 "February" 3 "March" 4 "April" 5 "May" 6 "June" 7 "July" 8 "August" 9 "September" 10 "October" 11 "November" 12 "December" ;
VAL_ 551 GetWeekday 1 "Monday" 2 "Tuesday" 3 "Wednesday" 4 "Thursday" 5 "Friday" 6 "Saturday" 0 "Sunday" ;
